VERSION ""

NS_ :

BS_:

BU_: Datalogger dSPACE

BO_ 7 New_Message_114: 8 Vector__XXX
 SG_ New_Signal_405 : 55|8@1+ (1,0) [0|0] "" Vector__XXX

BO_ 6 New_Message_113: 8 Vector__XXX
 SG_ New_Signal_404 : 39|8@1+ (1,0) [0|0] "" Vector__XXX

BO_ 5 New_Message_112: 8 Vector__XXX
 SG_ New_Signal_403 : 23|8@1+ (1,0) [0|0] "" Vector__XXX

BO_ 4 New_Message_111: 8 Vector__XXX
 SG_ New_Signal_402 : 7|8@1+ (1,0) [0|0] "" Vector__XXX

BO_ 3 New_Message_110: 8 Vector__XXX
 SG_ New_Signal_401 : 55|8@1+ (1,0) [0|0] "" Vector__XXX

BO_ 2 New_Message_109: 8 Vector__XXX
 SG_ New_Signal_400 : 39|8@1+ (1,0) [0|0] "" Vector__XXX

BO_ 1 New_Message_108: 8 Vector__XXX
 SG_ New_Signal_399 : 23|8@1+ (1,0) [0|0] "" Vector__XXX

BO_ 0 New_Message_107: 8 Vector__XXX
 SG_ New_Signal_398 : 7|8@1+ (1,0) [0|0] "" Vector__XXX

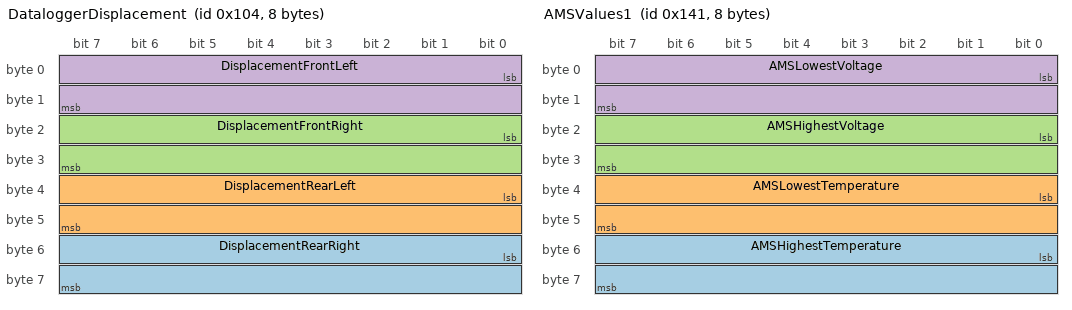
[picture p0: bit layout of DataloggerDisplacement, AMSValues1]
BO_ 260 DataloggerDisplacement: 8 Vector__XXX
 SG_ DisplacementRearRight : 48|16@1- (1,0) [0|0] "" Vector__XXX
 SG_ DisplacementRearLeft : 32|16@1- (1,0) [0|0] "" Vector__XXX
 SG_ DisplacementFrontRight : 16|16@1- (1,0) [0|0] "" Vector__XXX
 SG_ DisplacementFrontLeft : 0|16@1- (1,0) [0|0] "" Vector__XXX

BO_ 1319 EnergyMeterCurrentCounter: 6 Vector__XXX
 SG_ EMCurrentCounter : 23|32@0- (1,0) [0|0] "" Vector__XXX

BO_ 321 AMSValues1: 8 Vector__XXX
 SG_ AMSHighestTemperature : 48|16@1- (1,0) [0|0] "" Vector__XXX
 SG_ AMSLowestTemperature : 32|16@1- (1,0) [0|0] "" Vector__XXX
 SG_ AMSHighestVoltage : 16|16@1- (1,0) [0|0] "" Vector__XXX
 SG_ AMSLowestVoltage : 0|16@1- (1,0) [0|0] "" Vector__XXX

BO_ 1320 EnergyMeterEnergy: 6 Vector__XXX
 SG_ EMEnergy : 23|32@0- (1,0) [0|0] "" Vector__XXX

BO_ 1316 EnergyMeterVoltage3: 6 Vector__XXX
 SG_ EMVoltage3 : 23|32@0- (1,0) [0|0] "" Vector__XXX

BO_ 1315 EnergyMeterVoltageMC: 6 Vector__XXX
 SG_ EMVoltageMC : 7|32@0- (1,0) [0|0] "" Vector__XXX

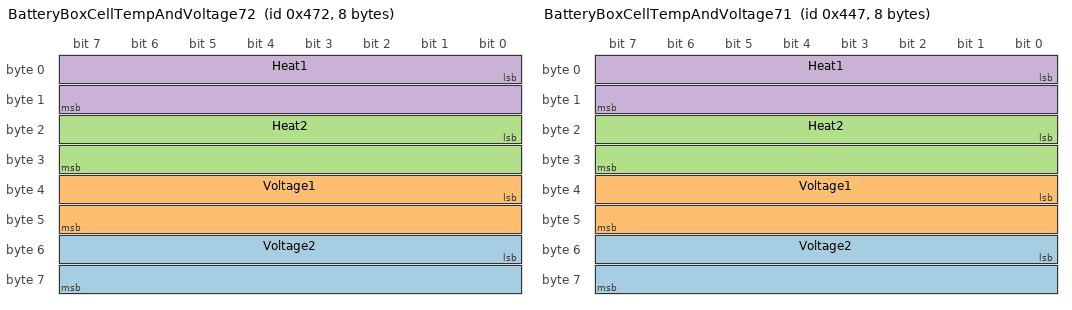
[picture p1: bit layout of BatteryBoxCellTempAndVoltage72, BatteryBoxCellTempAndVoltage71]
BO_ 1138 BatteryBoxCellTempAndVoltage72: 8 Vector__XXX
 SG_ Voltage2 : 48|16@1+ (0.001,0) [0|0] "" Vector__XXX
 SG_ Voltage1 : 32|16@1+ (0.001,0) [0|0] "" Vector__XXX
 SG_ Heat2 : 16|16@1+ (0.001,0) [0|0] "" Vector__XXX
 SG_ Heat1 : 0|16@1+ (0.001,0) [0|0] "" Vector__XXX

BO_ 1095 BatteryBoxCellTempAndVoltage71: 8 Vector__XXX
 SG_ Voltage2 : 48|16@1+ (0.001,0) [0|0] "" Vector__XXX
 SG_ Voltage1 : 32|16@1+ (0.001,0) [0|0] "" Vector__XXX
 SG_ Heat2 : 16|16@1+ (0.001,0) [0|0] "" Vector__XXX
 SG_ Heat1 : 0|16@1+ (0.001,0) [0|0] "" Vector__XXX

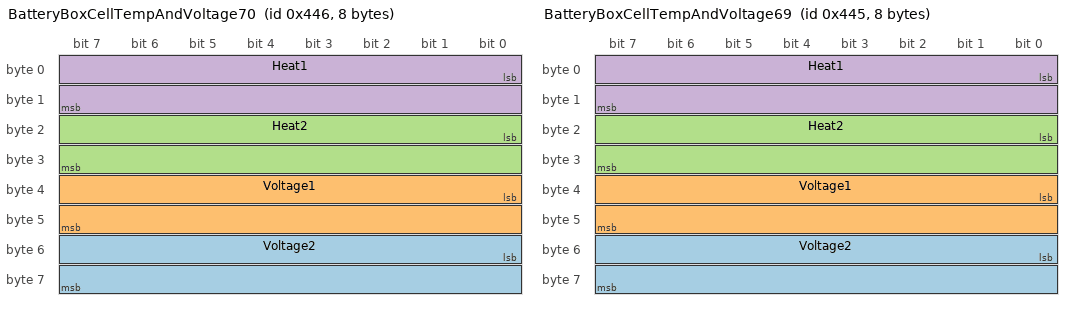
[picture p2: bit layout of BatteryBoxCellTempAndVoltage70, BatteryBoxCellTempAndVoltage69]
BO_ 1094 BatteryBoxCellTempAndVoltage70: 8 Vector__XXX
 SG_ Voltage2 : 48|16@1+ (0.001,0) [0|0] "" Vector__XXX
 SG_ Voltage1 : 32|16@1+ (0.001,0) [0|0] "" Vector__XXX
 SG_ Heat2 : 16|16@1+ (0.001,0) [0|0] "" Vector__XXX
 SG_ Heat1 : 0|16@1+ (0.001,0) [0|0] "" Vector__XXX

BO_ 1093 BatteryBoxCellTempAndVoltage69: 8 Vector__XXX
 SG_ Voltage2 : 48|16@1+ (0.001,0) [0|0] "" Vector__XXX
 SG_ Voltage1 : 32|16@1+ (0.001,0) [0|0] "" Vector__XXX
 SG_ Heat2 : 16|16@1+ (0.001,0) [0|0] "" Vector__XXX
 SG_ Heat1 : 0|16@1+ (0.001,0) [0|0] "" Vector__XXX

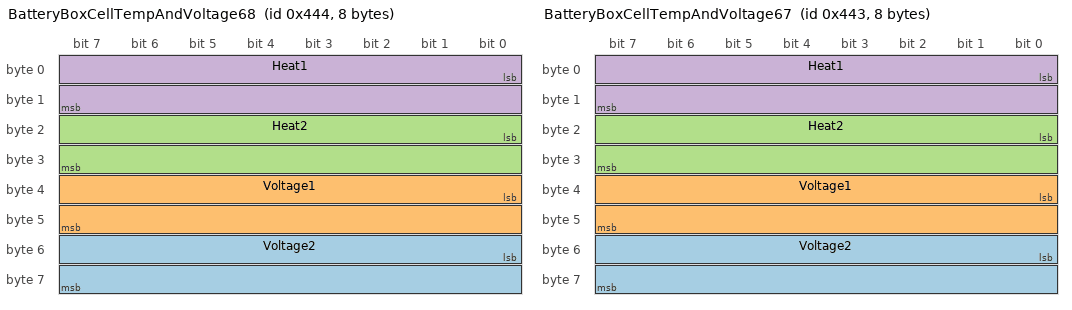
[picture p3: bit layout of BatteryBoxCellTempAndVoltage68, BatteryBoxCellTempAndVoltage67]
BO_ 1092 BatteryBoxCellTempAndVoltage68: 8 Vector__XXX
 SG_ Voltage2 : 48|16@1+ (0.001,0) [0|0] "" Vector__XXX
 SG_ Voltage1 : 32|16@1+ (0.001,0) [0|0] "" Vector__XXX
 SG_ Heat2 : 16|16@1+ (0.001,0) [0|0] "" Vector__XXX
 SG_ Heat1 : 0|16@1+ (0.001,0) [0|0] "" Vector__XXX

BO_ 1091 BatteryBoxCellTempAndVoltage67: 8 Vector__XXX
 SG_ Voltage2 : 48|16@1+ (0.001,0) [0|0] "" Vector__XXX
 SG_ Voltage1 : 32|16@1+ (0.001,0) [0|0] "" Vector__XXX
 SG_ Heat2 : 16|16@1+ (0.001,0) [0|0] "" Vector__XXX
 SG_ Heat1 : 0|16@1+ (0.001,0) [0|0] "" Vector__XXX

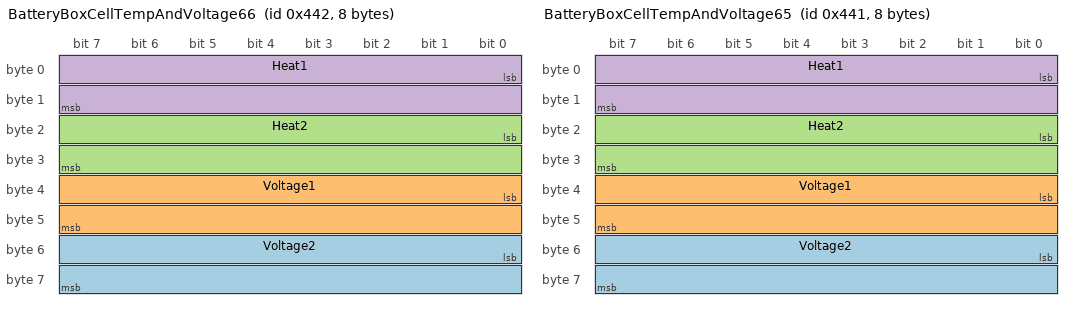
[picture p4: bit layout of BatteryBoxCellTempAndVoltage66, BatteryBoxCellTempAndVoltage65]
BO_ 1090 BatteryBoxCellTempAndVoltage66: 8 Vector__XXX
 SG_ Voltage2 : 48|16@1+ (0.001,0) [0|0] "" Vector__XXX
 SG_ Voltage1 : 32|16@1+ (0.001,0) [0|0] "" Vector__XXX
 SG_ Heat2 : 16|16@1+ (0.001,0) [0|0] "" Vector__XXX
 SG_ Heat1 : 0|16@1+ (0.001,0) [0|0] "" Vector__XXX

BO_ 1089 BatteryBoxCellTempAndVoltage65: 8 Vector__XXX
 SG_ Voltage2 : 48|16@1+ (0.001,0) [0|0] "" Vector__XXX
 SG_ Voltage1 : 32|16@1+ (0.001,0) [0|0] "" Vector__XXX
 SG_ Heat2 : 16|16@1+ (0.001,0) [0|0] "" Vector__XXX
 SG_ Heat1 : 0|16@1+ (0.001,0) [0|0] "" Vector__XXX

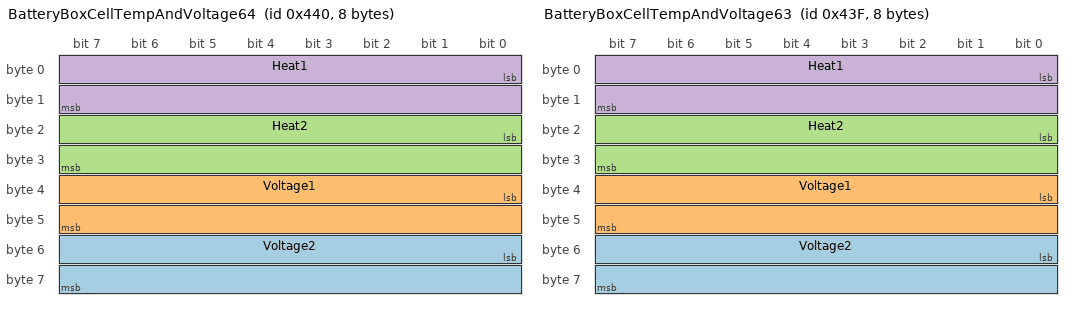
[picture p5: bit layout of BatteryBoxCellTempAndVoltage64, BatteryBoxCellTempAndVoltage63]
BO_ 1088 BatteryBoxCellTempAndVoltage64: 8 Vector__XXX
 SG_ Voltage2 : 48|16@1+ (0.001,0) [0|0] "" Vector__XXX
 SG_ Voltage1 : 32|16@1+ (0.001,0) [0|0] "" Vector__XXX
 SG_ Heat2 : 16|16@1+ (0.001,0) [0|0] "" Vector__XXX
 SG_ Heat1 : 0|16@1+ (0.001,0) [0|0] "" Vector__XXX

BO_ 1087 BatteryBoxCellTempAndVoltage63: 8 Vector__XXX
 SG_ Voltage2 : 48|16@1+ (0.001,0) [0|0] "" Vector__XXX
 SG_ Voltage1 : 32|16@1+ (0.001,0) [0|0] "" Vector__XXX
 SG_ Heat2 : 16|16@1+ (0.001,0) [0|0] "" Vector__XXX
 SG_ Heat1 : 0|16@1+ (0.001,0) [0|0] "" Vector__XXX

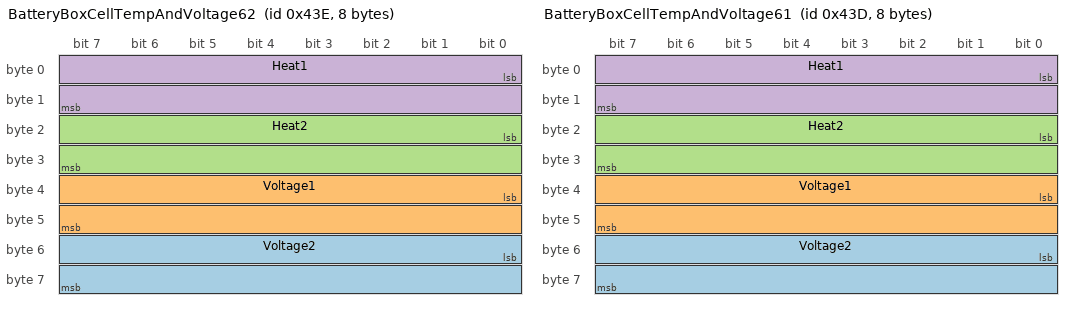
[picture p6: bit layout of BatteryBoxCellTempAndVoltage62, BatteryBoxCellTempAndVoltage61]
BO_ 1086 BatteryBoxCellTempAndVoltage62: 8 Vector__XXX
 SG_ Voltage2 : 48|16@1+ (0.001,0) [0|0] "" Vector__XXX
 SG_ Voltage1 : 32|16@1+ (0.001,0) [0|0] "" Vector__XXX
 SG_ Heat2 : 16|16@1+ (0.001,0) [0|0] "" Vector__XXX
 SG_ Heat1 : 0|16@1+ (0.001,0) [0|0] "" Vector__XXX

BO_ 1085 BatteryBoxCellTempAndVoltage61: 8 Vector__XXX
 SG_ Voltage2 : 48|16@1+ (0.001,0) [0|0] "" Vector__XXX
 SG_ Voltage1 : 32|16@1+ (0.001,0) [0|0] "" Vector__XXX
 SG_ Heat2 : 16|16@1+ (0.001,0) [0|0] "" Vector__XXX
 SG_ Heat1 : 0|16@1+ (0.001,0) [0|0] "" Vector__XXX

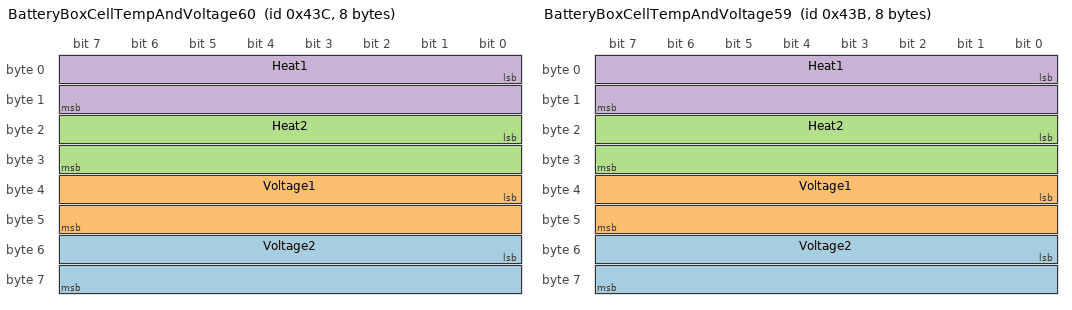
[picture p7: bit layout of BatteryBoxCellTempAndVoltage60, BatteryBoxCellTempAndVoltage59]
BO_ 1084 BatteryBoxCellTempAndVoltage60: 8 Vector__XXX
 SG_ Voltage2 : 48|16@1+ (0.001,0) [0|0] "" Vector__XXX
 SG_ Voltage1 : 32|16@1+ (0.001,0) [0|0] "" Vector__XXX
 SG_ Heat2 : 16|16@1+ (0.001,0) [0|0] "" Vector__XXX
 SG_ Heat1 : 0|16@1+ (0.001,0) [0|0] "" Vector__XXX

BO_ 1083 BatteryBoxCellTempAndVoltage59: 8 Vector__XXX
 SG_ Voltage2 : 48|16@1+ (0.001,0) [0|0] "" Vector__XXX
 SG_ Voltage1 : 32|16@1+ (0.001,0) [0|0] "" Vector__XXX
 SG_ Heat2 : 16|16@1+ (0.001,0) [0|0] "" Vector__XXX
 SG_ Heat1 : 0|16@1+ (0.001,0) [0|0] "" Vector__XXX

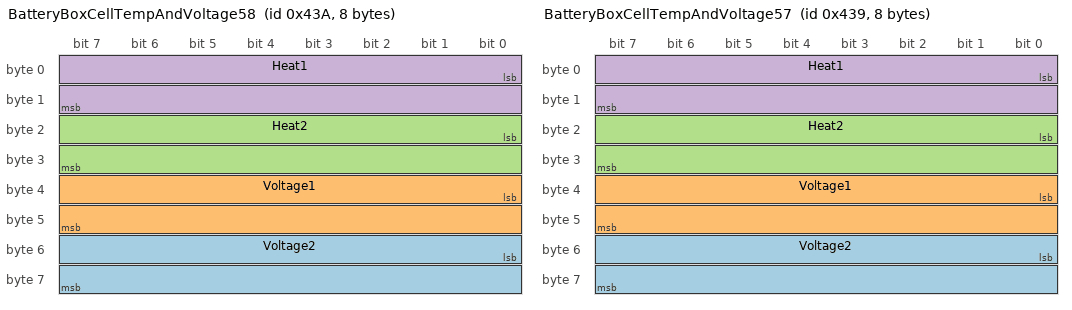
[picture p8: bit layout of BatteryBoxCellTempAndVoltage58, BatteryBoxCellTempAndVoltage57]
BO_ 1082 BatteryBoxCellTempAndVoltage58: 8 Vector__XXX
 SG_ Voltage2 : 48|16@1+ (0.001,0) [0|0] "" Vector__XXX
 SG_ Voltage1 : 32|16@1+ (0.001,0) [0|0] "" Vector__XXX
 SG_ Heat2 : 16|16@1+ (0.001,0) [0|0] "" Vector__XXX
 SG_ Heat1 : 0|16@1+ (0.001,0) [0|0] "" Vector__XXX

BO_ 1081 BatteryBoxCellTempAndVoltage57: 8 Vector__XXX
 SG_ Voltage2 : 48|16@1+ (0.001,0) [0|0] "" Vector__XXX
 SG_ Voltage1 : 32|16@1+ (0.001,0) [0|0] "" Vector__XXX
 SG_ Heat2 : 16|16@1+ (0.001,0) [0|0] "" Vector__XXX
 SG_ Heat1 : 0|16@1+ (0.001,0) [0|0] "" Vector__XXX

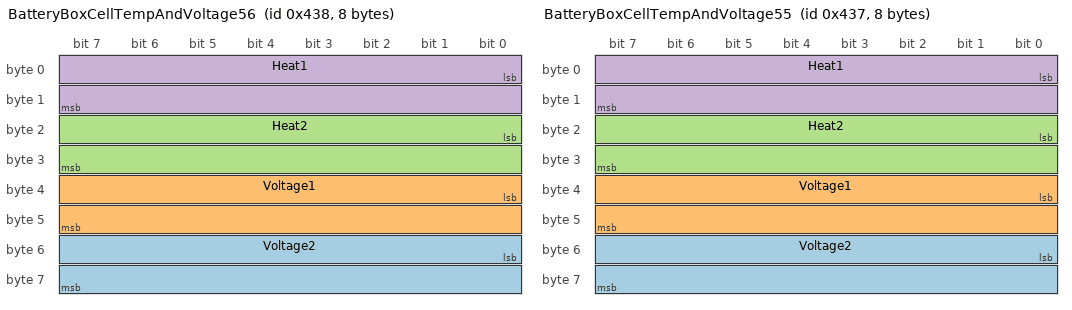
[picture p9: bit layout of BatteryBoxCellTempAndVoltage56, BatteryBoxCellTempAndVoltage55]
BO_ 1080 BatteryBoxCellTempAndVoltage56: 8 Vector__XXX
 SG_ Voltage2 : 48|16@1+ (0.001,0) [0|0] "" Vector__XXX
 SG_ Voltage1 : 32|16@1+ (0.001,0) [0|0] "" Vector__XXX
 SG_ Heat2 : 16|16@1+ (0.001,0) [0|0] "" Vector__XXX
 SG_ Heat1 : 0|16@1+ (0.001,0) [0|0] "" Vector__XXX

BO_ 1079 BatteryBoxCellTempAndVoltage55: 8 Vector__XXX
 SG_ Voltage2 : 48|16@1+ (0.001,0) [0|0] "" Vector__XXX
 SG_ Voltage1 : 32|16@1+ (0.001,0) [0|0] "" Vector__XXX
 SG_ Heat2 : 16|16@1+ (0.001,0) [0|0] "" Vector__XXX
 SG_ Heat1 : 0|16@1+ (0.001,0) [0|0] "" Vector__XXX

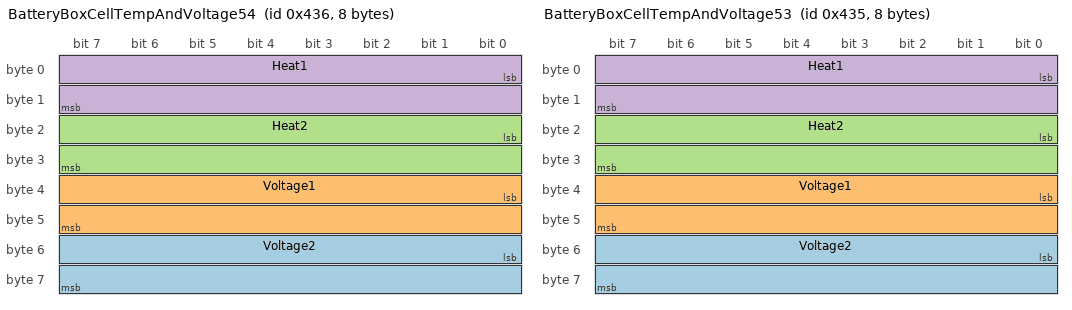
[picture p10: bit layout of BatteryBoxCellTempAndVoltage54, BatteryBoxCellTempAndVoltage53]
BO_ 1078 BatteryBoxCellTempAndVoltage54: 8 Vector__XXX
 SG_ Voltage2 : 48|16@1+ (0.001,0) [0|0] "" Vector__XXX
 SG_ Voltage1 : 32|16@1+ (0.001,0) [0|0] "" Vector__XXX
 SG_ Heat2 : 16|16@1+ (0.001,0) [0|0] "" Vector__XXX
 SG_ Heat1 : 0|16@1+ (0.001,0) [0|0] "" Vector__XXX

BO_ 1077 BatteryBoxCellTempAndVoltage53: 8 Vector__XXX
 SG_ Voltage2 : 48|16@1+ (0.001,0) [0|0] "" Vector__XXX
 SG_ Voltage1 : 32|16@1+ (0.001,0) [0|0] "" Vector__XXX
 SG_ Heat2 : 16|16@1+ (0.001,0) [0|0] "" Vector__XXX
 SG_ Heat1 : 0|16@1+ (0.001,0) [0|0] "" Vector__XXX

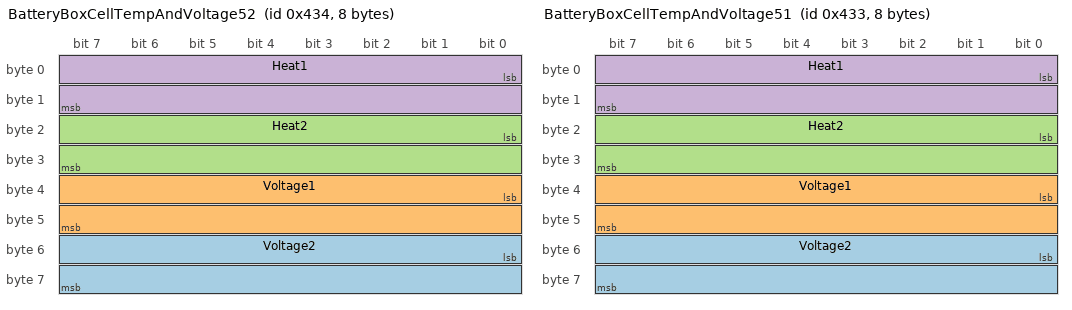
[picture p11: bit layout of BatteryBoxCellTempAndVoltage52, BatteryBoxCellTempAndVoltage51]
BO_ 1076 BatteryBoxCellTempAndVoltage52: 8 Vector__XXX
 SG_ Voltage2 : 48|16@1+ (0.001,0) [0|0] "" Vector__XXX
 SG_ Voltage1 : 32|16@1+ (0.001,0) [0|0] "" Vector__XXX
 SG_ Heat2 : 16|16@1+ (0.001,0) [0|0] "" Vector__XXX
 SG_ Heat1 : 0|16@1+ (0.001,0) [0|0] "" Vector__XXX

BO_ 1075 BatteryBoxCellTempAndVoltage51: 8 Vector__XXX
 SG_ Voltage2 : 48|16@1+ (0.001,0) [0|0] "" Vector__XXX
 SG_ Voltage1 : 32|16@1+ (0.001,0) [0|0] "" Vector__XXX
 SG_ Heat2 : 16|16@1+ (0.001,0) [0|0] "" Vector__XXX
 SG_ Heat1 : 0|16@1+ (0.001,0) [0|0] "" Vector__XXX

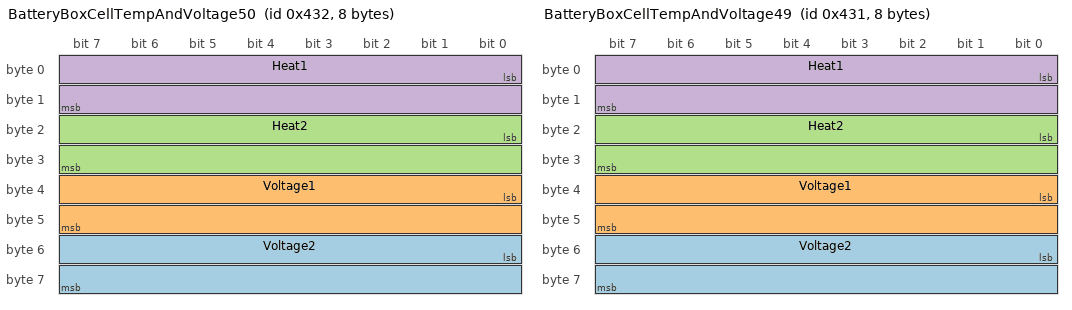
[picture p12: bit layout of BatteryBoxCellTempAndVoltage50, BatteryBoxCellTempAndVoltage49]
BO_ 1074 BatteryBoxCellTempAndVoltage50: 8 Vector__XXX
 SG_ Voltage2 : 48|16@1+ (0.001,0) [0|0] "" Vector__XXX
 SG_ Voltage1 : 32|16@1+ (0.001,0) [0|0] "" Vector__XXX
 SG_ Heat2 : 16|16@1+ (0.001,0) [0|0] "" Vector__XXX
 SG_ Heat1 : 0|16@1+ (0.001,0) [0|0] "" Vector__XXX

BO_ 1073 BatteryBoxCellTempAndVoltage49: 8 Vector__XXX
 SG_ Voltage2 : 48|16@1+ (0.001,0) [0|0] "" Vector__XXX
 SG_ Voltage1 : 32|16@1+ (0.001,0) [0|0] "" Vector__XXX
 SG_ Heat2 : 16|16@1+ (0.001,0) [0|0] "" Vector__XXX
 SG_ Heat1 : 0|16@1+ (0.001,0) [0|0] "" Vector__XXX

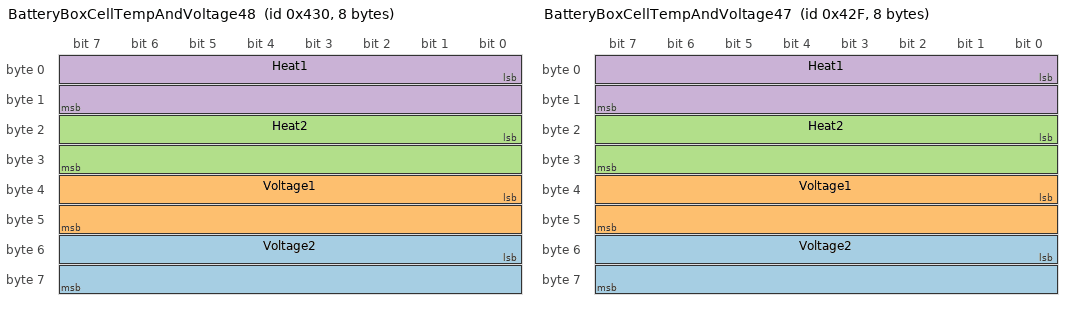
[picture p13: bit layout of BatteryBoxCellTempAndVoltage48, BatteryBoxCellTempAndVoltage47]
BO_ 1072 BatteryBoxCellTempAndVoltage48: 8 Vector__XXX
 SG_ Voltage2 : 48|16@1+ (0.001,0) [0|0] "" Vector__XXX
 SG_ Voltage1 : 32|16@1+ (0.001,0) [0|0] "" Vector__XXX
 SG_ Heat2 : 16|16@1+ (0.001,0) [0|0] "" Vector__XXX
 SG_ Heat1 : 0|16@1+ (0.001,0) [0|0] "" Vector__XXX

BO_ 1071 BatteryBoxCellTempAndVoltage47: 8 Vector__XXX
 SG_ Voltage2 : 48|16@1+ (0.001,0) [0|0] "" Vector__XXX
 SG_ Voltage1 : 32|16@1+ (0.001,0) [0|0] "" Vector__XXX
 SG_ Heat2 : 16|16@1+ (0.001,0) [0|0] "" Vector__XXX
 SG_ Heat1 : 0|16@1+ (0.001,0) [0|0] "" Vector__XXX

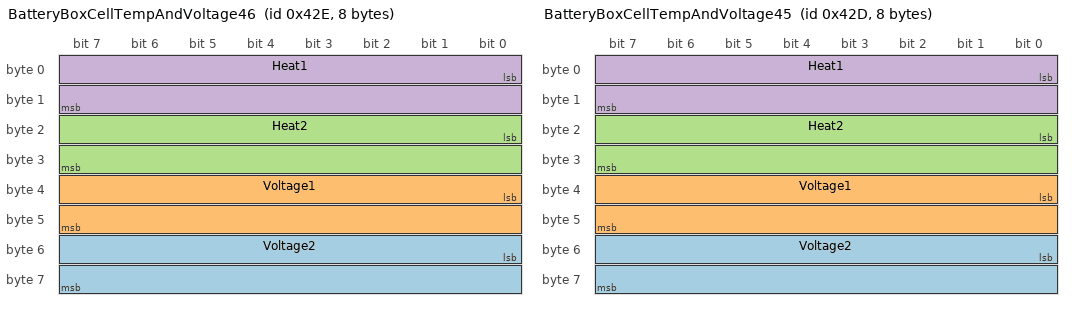
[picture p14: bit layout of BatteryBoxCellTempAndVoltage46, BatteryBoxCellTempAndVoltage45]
BO_ 1070 BatteryBoxCellTempAndVoltage46: 8 Vector__XXX
 SG_ Voltage2 : 48|16@1+ (0.001,0) [0|0] "" Vector__XXX
 SG_ Voltage1 : 32|16@1+ (0.001,0) [0|0] "" Vector__XXX
 SG_ Heat2 : 16|16@1+ (0.001,0) [0|0] "" Vector__XXX
 SG_ Heat1 : 0|16@1+ (0.001,0) [0|0] "" Vector__XXX

BO_ 1069 BatteryBoxCellTempAndVoltage45: 8 Vector__XXX
 SG_ Voltage2 : 48|16@1+ (0.001,0) [0|0] "" Vector__XXX
 SG_ Voltage1 : 32|16@1+ (0.001,0) [0|0] "" Vector__XXX
 SG_ Heat2 : 16|16@1+ (0.001,0) [0|0] "" Vector__XXX
 SG_ Heat1 : 0|16@1+ (0.001,0) [0|0] "" Vector__XXX

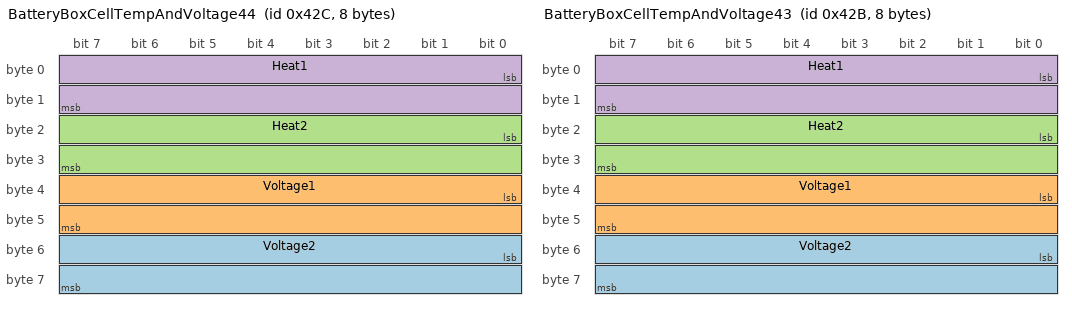
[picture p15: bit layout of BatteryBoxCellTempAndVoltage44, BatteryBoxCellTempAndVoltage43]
BO_ 1068 BatteryBoxCellTempAndVoltage44: 8 Vector__XXX
 SG_ Voltage2 : 48|16@1+ (0.001,0) [0|0] "" Vector__XXX
 SG_ Voltage1 : 32|16@1+ (0.001,0) [0|0] "" Vector__XXX
 SG_ Heat2 : 16|16@1+ (0.001,0) [0|0] "" Vector__XXX
 SG_ Heat1 : 0|16@1+ (0.001,0) [0|0] "" Vector__XXX

BO_ 1067 BatteryBoxCellTempAndVoltage43: 8 Vector__XXX
 SG_ Voltage2 : 48|16@1+ (0.001,0) [0|0] "" Vector__XXX
 SG_ Voltage1 : 32|16@1+ (0.001,0) [0|0] "" Vector__XXX
 SG_ Heat2 : 16|16@1+ (0.001,0) [0|0] "" Vector__XXX
 SG_ Heat1 : 0|16@1+ (0.001,0) [0|0] "" Vector__XXX

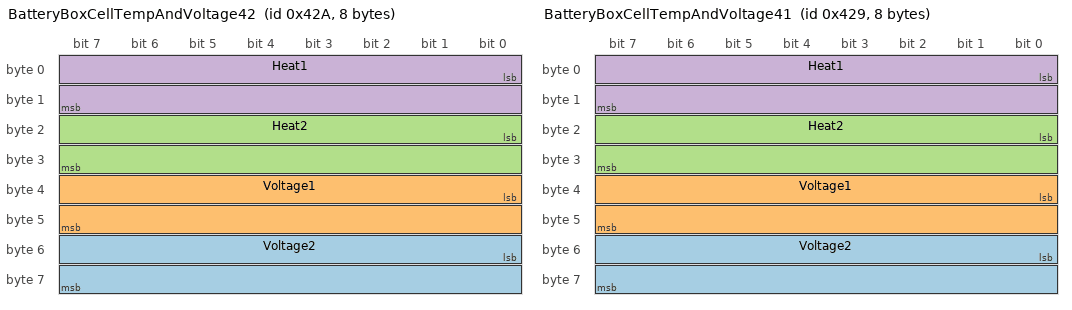
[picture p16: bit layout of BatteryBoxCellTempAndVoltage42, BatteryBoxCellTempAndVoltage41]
BO_ 1066 BatteryBoxCellTempAndVoltage42: 8 Vector__XXX
 SG_ Voltage2 : 48|16@1+ (0.001,0) [0|0] "" Vector__XXX
 SG_ Voltage1 : 32|16@1+ (0.001,0) [0|0] "" Vector__XXX
 SG_ Heat2 : 16|16@1+ (0.001,0) [0|0] "" Vector__XXX
 SG_ Heat1 : 0|16@1+ (0.001,0) [0|0] "" Vector__XXX

BO_ 1065 BatteryBoxCellTempAndVoltage41: 8 Vector__XXX
 SG_ Voltage2 : 48|16@1+ (0.001,0) [0|0] "" Vector__XXX
 SG_ Voltage1 : 32|16@1+ (0.001,0) [0|0] "" Vector__XXX
 SG_ Heat2 : 16|16@1+ (0.001,0) [0|0] "" Vector__XXX
 SG_ Heat1 : 0|16@1+ (0.001,0) [0|0] "" Vector__XXX

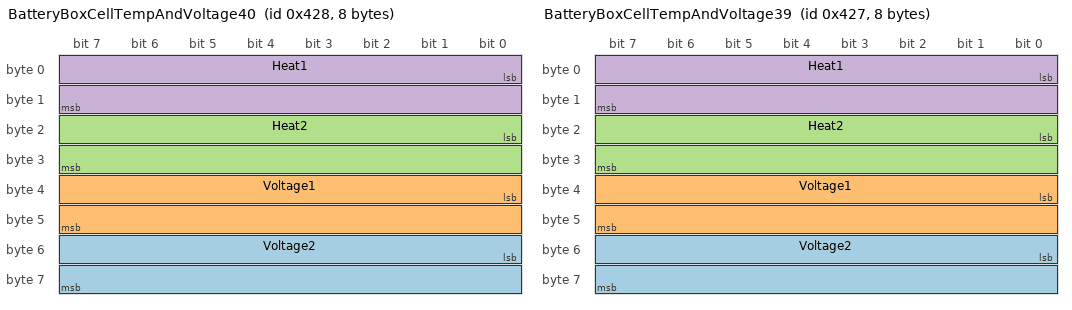
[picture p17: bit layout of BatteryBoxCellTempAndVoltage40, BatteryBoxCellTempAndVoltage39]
BO_ 1064 BatteryBoxCellTempAndVoltage40: 8 Vector__XXX
 SG_ Voltage2 : 48|16@1+ (0.001,0) [0|0] "" Vector__XXX
 SG_ Voltage1 : 32|16@1+ (0.001,0) [0|0] "" Vector__XXX
 SG_ Heat2 : 16|16@1+ (0.001,0) [0|0] "" Vector__XXX
 SG_ Heat1 : 0|16@1+ (0.001,0) [0|0] "" Vector__XXX

BO_ 1063 BatteryBoxCellTempAndVoltage39: 8 Vector__XXX
 SG_ Voltage2 : 48|16@1+ (0.001,0) [0|0] "" Vector__XXX
 SG_ Voltage1 : 32|16@1+ (0.001,0) [0|0] "" Vector__XXX
 SG_ Heat2 : 16|16@1+ (0.001,0) [0|0] "" Vector__XXX
 SG_ Heat1 : 0|16@1+ (0.001,0) [0|0] "" Vector__XXX

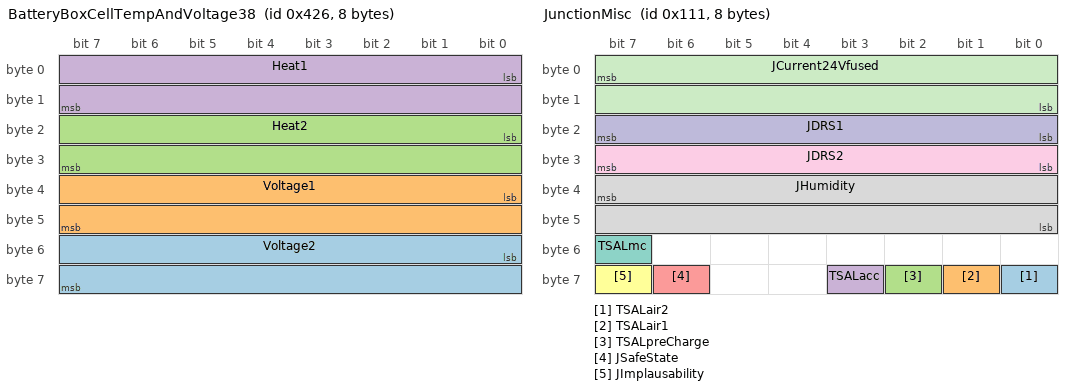
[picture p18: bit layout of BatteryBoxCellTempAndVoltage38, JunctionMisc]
BO_ 1062 BatteryBoxCellTempAndVoltage38: 8 Vector__XXX
 SG_ Voltage2 : 48|16@1+ (0.001,0) [0|0] "" Vector__XXX
 SG_ Voltage1 : 32|16@1+ (0.001,0) [0|0] "" Vector__XXX
 SG_ Heat2 : 16|16@1+ (0.001,0) [0|0] "" Vector__XXX
 SG_ Heat1 : 0|16@1+ (0.001,0) [0|0] "" Vector__XXX

BO_ 1061 BatteryBoxCellTempAndVoltage37: 8 Vector__XXX
 SG_ Voltage2 : 48|16@1+ (0.001,0) [0|0] "" Vector__XXX
 SG_ Voltage1 : 32|16@1+ (0.001,0) [0|0] "" Vector__XXX
 SG_ Heat2 : 16|16@1+ (0.001,0) [0|0] "" Vector__XXX
 SG_ Heat1 : 0|16@1+ (0.001,0) [0|0] "" Vector__XXX

BO_ 1060 BatteryBoxCellTempAndVoltage36: 8 Vector__XXX
 SG_ Voltage2 : 48|16@1+ (0.001,0) [0|0] "" Vector__XXX
 SG_ Voltage1 : 32|16@1+ (0.001,0) [0|0] "" Vector__XXX
 SG_ Heat2 : 16|16@1+ (0.001,0) [0|0] "" Vector__XXX
 SG_ Heat1 : 0|16@1+ (0.001,0) [0|0] "" Vector__XXX

BO_ 1059 BatteryBoxCellTempAndVoltage35: 8 Vector__XXX
 SG_ Voltage2 : 48|16@1+ (0.001,0) [0|0] "" Vector__XXX
 SG_ Voltage1 : 32|16@1+ (0.001,0) [0|0] "" Vector__XXX
 SG_ Heat2 : 16|16@1+ (0.001,0) [0|0] "" Vector__XXX
 SG_ Heat1 : 0|16@1+ (0.001,0) [0|0] "" Vector__XXX

BO_ 1058 BatteryBoxCellTempAndVoltage34: 8 Vector__XXX
 SG_ Voltage2 : 48|16@1+ (0.001,0) [0|0] "" Vector__XXX
 SG_ Voltage1 : 32|16@1+ (0.001,0) [0|0] "" Vector__XXX
 SG_ Heat2 : 16|16@1+ (0.001,0) [0|0] "" Vector__XXX
 SG_ Heat1 : 0|16@1+ (0.001,0) [0|0] "" Vector__XXX

BO_ 1057 BatteryBoxCellTempAndVoltage33: 8 Vector__XXX
 SG_ Voltage2 : 48|16@1+ (0.001,0) [0|0] "" Vector__XXX
 SG_ Voltage1 : 32|16@1+ (0.001,0) [0|0] "" Vector__XXX
 SG_ Heat2 : 16|16@1+ (0.001,0) [0|0] "" Vector__XXX
 SG_ Heat1 : 0|16@1+ (0.001,0) [0|0] "" Vector__XXX

BO_ 1056 BatteryBoxCellTempAndVoltage32: 8 Vector__XXX
 SG_ Voltage2 : 48|16@1+ (0.001,0) [0|0] "" Vector__XXX
 SG_ Voltage1 : 32|16@1+ (0.001,0) [0|0] "" Vector__XXX
 SG_ Heat2 : 16|16@1+ (0.001,0) [0|0] "" Vector__XXX
 SG_ Heat1 : 0|16@1+ (0.001,0) [0|0] "" Vector__XXX

BO_ 1055 BatteryBoxCellTempAndVoltage31: 8 Vector__XXX
 SG_ Voltage2 : 48|16@1+ (0.001,0) [0|0] "" Vector__XXX
 SG_ Voltage1 : 32|16@1+ (0.001,0) [0|0] "" Vector__XXX
 SG_ Heat2 : 16|16@1+ (0.001,0) [0|0] "" Vector__XXX
 SG_ Heat1 : 0|16@1+ (0.001,0) [0|0] "" Vector__XXX

BO_ 1054 BatteryBoxCellTempAndVoltage30: 8 Vector__XXX
 SG_ Voltage2 : 48|16@1+ (0.001,0) [0|0] "" Vector__XXX
 SG_ Voltage1 : 32|16@1+ (0.001,0) [0|0] "" Vector__XXX
 SG_ Heat2 : 16|16@1+ (0.001,0) [0|0] "" Vector__XXX
 SG_ Heat1 : 0|16@1+ (0.001,0) [0|0] "" Vector__XXX

BO_ 1053 BatteryBoxCellTempAndVoltage29: 8 Vector__XXX
 SG_ Voltage2 : 48|16@1+ (0.001,0) [0|0] "" Vector__XXX
 SG_ Voltage1 : 32|16@1+ (0.001,0) [0|0] "" Vector__XXX
 SG_ Heat2 : 16|16@1+ (0.001,0) [0|0] "" Vector__XXX
 SG_ Heat1 : 0|16@1+ (0.001,0) [0|0] "" Vector__XXX

BO_ 1052 BatteryBoxCellTempAndVoltage28: 8 Vector__XXX
 SG_ Voltage2 : 48|16@1+ (0.001,0) [0|0] "" Vector__XXX
 SG_ Voltage1 : 32|16@1+ (0.001,0) [0|0] "" Vector__XXX
 SG_ Heat2 : 16|16@1+ (0.001,0) [0|0] "" Vector__XXX
 SG_ Heat1 : 0|16@1+ (0.001,0) [0|0] "" Vector__XXX

BO_ 1051 BatteryBoxCellTempAndVoltage27: 8 Vector__XXX
 SG_ Voltage2 : 48|16@1+ (0.001,0) [0|0] "" Vector__XXX
 SG_ Voltage1 : 32|16@1+ (0.001,0) [0|0] "" Vector__XXX
 SG_ Heat2 : 16|16@1+ (0.001,0) [0|0] "" Vector__XXX
 SG_ Heat1 : 0|16@1+ (0.001,0) [0|0] "" Vector__XXX

BO_ 1050 BatteryBoxCellTempAndVoltage26: 8 Vector__XXX
 SG_ Voltage2 : 48|16@1+ (0.001,0) [0|0] "" Vector__XXX
 SG_ Voltage1 : 32|16@1+ (0.001,0) [0|0] "" Vector__XXX
 SG_ Heat2 : 16|16@1+ (0.001,0) [0|0] "" Vector__XXX
 SG_ Heat1 : 0|16@1+ (0.001,0) [0|0] "" Vector__XXX

BO_ 1049 BatteryBoxCellTempAndVoltage25: 8 Vector__XXX
 SG_ Voltage2 : 48|16@1+ (0.001,0) [0|0] "" Vector__XXX
 SG_ Voltage1 : 32|16@1+ (0.001,0) [0|0] "" Vector__XXX
 SG_ Heat2 : 16|16@1+ (0.001,0) [0|0] "" Vector__XXX
 SG_ Heat1 : 0|16@1+ (0.001,0) [0|0] "" Vector__XXX

BO_ 1048 BatteryBoxCellTempAndVoltage24: 8 Vector__XXX
 SG_ Voltage2 : 48|16@1+ (0.001,0) [0|0] "" Vector__XXX
 SG_ Voltage1 : 32|16@1+ (0.001,0) [0|0] "" Vector__XXX
 SG_ Heat2 : 16|16@1+ (0.001,0) [0|0] "" Vector__XXX
 SG_ Heat1 : 0|16@1+ (0.001,0) [0|0] "" Vector__XXX

BO_ 1047 BatteryBoxCellTempAndVoltage23: 8 Vector__XXX
 SG_ Voltage2 : 48|16@1+ (0.001,0) [0|0] "" Vector__XXX
 SG_ Voltage1 : 32|16@1+ (0.001,0) [0|0] "" Vector__XXX
 SG_ Heat2 : 16|16@1+ (0.001,0) [0|0] "" Vector__XXX
 SG_ Heat1 : 0|16@1+ (0.001,0) [0|0] "" Vector__XXX

BO_ 1046 BatteryBoxCellTempAndVoltage22: 8 Vector__XXX
 SG_ Voltage2 : 48|16@1+ (0.001,0) [0|0] "" Vector__XXX
 SG_ Voltage1 : 32|16@1+ (0.001,0) [0|0] "" Vector__XXX
 SG_ Heat2 : 16|16@1+ (0.001,0) [0|0] "" Vector__XXX
 SG_ Heat1 : 0|16@1+ (0.001,0) [0|0] "" Vector__XXX

BO_ 1045 BatteryBoxCellTempAndVoltage21: 8 Vector__XXX
 SG_ Voltage2 : 48|16@1+ (0.001,0) [0|0] "" Vector__XXX
 SG_ Voltage1 : 32|16@1+ (0.001,0) [0|0] "" Vector__XXX
 SG_ Heat2 : 16|16@1+ (0.001,0) [0|0] "" Vector__XXX
 SG_ Heat1 : 0|16@1+ (0.001,0) [0|0] "" Vector__XXX

BO_ 1044 BatteryBoxCellTempAndVoltage20: 8 Vector__XXX
 SG_ Voltage2 : 48|16@1+ (0.001,0) [0|0] "" Vector__XXX
 SG_ Voltage1 : 32|16@1+ (0.001,0) [0|0] "" Vector__XXX
 SG_ Heat2 : 16|16@1+ (0.001,0) [0|0] "" Vector__XXX
 SG_ Heat1 : 0|16@1+ (0.001,0) [0|0] "" Vector__XXX

BO_ 1043 BatteryBoxCellTempAndVoltage19: 8 Vector__XXX
 SG_ Voltage2 : 48|16@1+ (0.001,0) [0|0] "" Vector__XXX
 SG_ Voltage1 : 32|16@1+ (0.001,0) [0|0] "" Vector__XXX
 SG_ Heat2 : 16|16@1+ (0.001,0) [0|0] "" Vector__XXX
 SG_ Heat1 : 0|16@1+ (0.001,0) [0|0] "" Vector__XXX

BO_ 1042 BatteryBoxCellTempAndVoltage18: 8 Vector__XXX
 SG_ Voltage2 : 48|16@1+ (0.001,0) [0|0] "" Vector__XXX
 SG_ Voltage1 : 32|16@1+ (0.001,0) [0|0] "" Vector__XXX
 SG_ Heat2 : 16|16@1+ (0.001,0) [0|0] "" Vector__XXX
 SG_ Heat1 : 0|16@1+ (0.001,0) [0|0] "" Vector__XXX

BO_ 1024 BatteryBoxCellTempAndVoltage17: 8 Vector__XXX
 SG_ Voltage2 : 48|16@1+ (0.001,0) [0|0] "" Vector__XXX
 SG_ Voltage1 : 32|16@1+ (0.001,0) [0|0] "" Vector__XXX
 SG_ Heat2 : 16|16@1+ (0.001,0) [0|0] "" Vector__XXX
 SG_ Heat1 : 0|16@1+ (0.001,0) [0|0] "" Vector__XXX

BO_ 1040 BatteryBoxCellTempAndVoltage16: 8 Vector__XXX
 SG_ Voltage2 : 48|16@1+ (0.001,0) [0|0] "" Vector__XXX
 SG_ Voltage1 : 32|16@1+ (0.001,0) [0|0] "" Vector__XXX
 SG_ Heat2 : 16|16@1+ (0.001,0) [0|0] "" Vector__XXX
 SG_ Heat1 : 0|16@1+ (0.001,0) [0|0] "" Vector__XXX

BO_ 1039 BatteryBoxCellTempAndVoltage15: 8 Vector__XXX
 SG_ Voltage2 : 48|16@1+ (0.001,0) [0|0] "" Vector__XXX
 SG_ Voltage1 : 32|16@1+ (0.001,0) [0|0] "" Vector__XXX
 SG_ Heat2 : 16|16@1+ (0.001,0) [0|0] "" Vector__XXX
 SG_ Heat1 : 0|16@1+ (0.001,0) [0|0] "" Vector__XXX

BO_ 1038 BatteryBoxCellTempAndVoltage14: 8 Vector__XXX
 SG_ Voltage2 : 48|16@1+ (0.001,0) [0|0] "" Vector__XXX
 SG_ Voltage1 : 32|16@1+ (0.001,0) [0|0] "" Vector__XXX
 SG_ Heat2 : 16|16@1+ (0.001,0) [0|0] "" Vector__XXX
 SG_ Heat1 : 0|16@1+ (0.001,0) [0|0] "" Vector__XXX

BO_ 1037 BatteryBoxCellTempAndVoltage13: 8 Vector__XXX
 SG_ Voltage2 : 48|16@1+ (0.001,0) [0|0] "" Vector__XXX
 SG_ Voltage1 : 32|16@1+ (0.001,0) [0|0] "" Vector__XXX
 SG_ Heat2 : 16|16@1+ (0.001,0) [0|0] "" Vector__XXX
 SG_ Heat1 : 0|16@1+ (0.001,0) [0|0] "" Vector__XXX

BO_ 1036 BatteryBoxCellTempAndVoltage12: 8 Vector__XXX
 SG_ Voltage2 : 48|16@1+ (0.001,0) [0|0] "" Vector__XXX
 SG_ Voltage1 : 32|16@1+ (0.001,0) [0|0] "" Vector__XXX
 SG_ Heat2 : 16|16@1+ (0.001,0) [0|0] "" Vector__XXX
 SG_ Heat1 : 0|16@1+ (0.001,0) [0|0] "" Vector__XXX

BO_ 1035 BatteryBoxCellTempAndVoltage11: 8 Vector__XXX
 SG_ Voltage2 : 48|16@1+ (0.001,0) [0|0] "" Vector__XXX
 SG_ Voltage1 : 32|16@1+ (0.001,0) [0|0] "" Vector__XXX
 SG_ Heat2 : 16|16@1+ (0.001,0) [0|0] "" Vector__XXX
 SG_ Heat1 : 0|16@1+ (0.001,0) [0|0] "" Vector__XXX

BO_ 1034 BatteryBoxCellTempAndVoltage10: 8 Vector__XXX
 SG_ Voltage2 : 48|16@1+ (0.001,0) [0|0] "" Vector__XXX
 SG_ Voltage1 : 32|16@1+ (0.001,0) [0|0] "" Vector__XXX
 SG_ Heat2 : 16|16@1+ (0.001,0) [0|0] "" Vector__XXX
 SG_ Heat1 : 0|16@1+ (0.001,0) [0|0] "" Vector__XXX

BO_ 1033 BatteryBoxCellTempAndVoltage9: 8 Vector__XXX
 SG_ Voltage2 : 48|16@1+ (0.001,0) [0|0] "" Vector__XXX
 SG_ Voltage1 : 32|16@1+ (0.001,0) [0|0] "" Vector__XXX
 SG_ Heat2 : 16|16@1+ (0.001,0) [0|0] "" Vector__XXX
 SG_ Heat1 : 0|16@1+ (0.001,0) [0|0] "" Vector__XXX

BO_ 1032 BatteryBoxCellTempAndVoltage8: 8 Vector__XXX
 SG_ Voltage2 : 48|16@1+ (0.001,0) [0|0] "" Vector__XXX
 SG_ Voltage1 : 32|16@1+ (0.001,0) [0|0] "" Vector__XXX
 SG_ Heat2 : 16|16@1+ (0.001,0) [0|0] "" Vector__XXX
 SG_ Heat1 : 0|16@1+ (0.001,0) [0|0] "" Vector__XXX

BO_ 1031 BatteryBoxCellTempAndVoltage7: 8 Vector__XXX
 SG_ Voltage2 : 48|16@1+ (0.001,0) [0|0] "" Vector__XXX
 SG_ Voltage1 : 32|16@1+ (0.001,0) [0|0] "" Vector__XXX
 SG_ Heat2 : 16|16@1+ (0.001,0) [0|0] "" Vector__XXX
 SG_ Heat1 : 0|16@1+ (0.001,0) [0|0] "" Vector__XXX

BO_ 1030 BatteryBoxCellTempAndVoltage6: 8 Vector__XXX
 SG_ Voltage2 : 48|16@1+ (0.001,0) [0|0] "" Vector__XXX
 SG_ Voltage1 : 32|16@1+ (0.001,0) [0|0] "" Vector__XXX
 SG_ Heat2 : 16|16@1+ (0.001,0) [0|0] "" Vector__XXX
 SG_ Heat1 : 0|16@1+ (0.001,0) [0|0] "" Vector__XXX

BO_ 1029 BatteryBoxCellTempAndVoltage5: 8 Vector__XXX
 SG_ Voltage2 : 48|16@1+ (0.001,0) [0|0] "" Vector__XXX
 SG_ Voltage1 : 32|16@1+ (0.001,0) [0|0] "" Vector__XXX
 SG_ Heat2 : 16|16@1+ (0.001,0) [0|0] "" Vector__XXX
 SG_ Heat1 : 0|16@1+ (0.001,0) [0|0] "" Vector__XXX

BO_ 1028 BatteryBoxCellTempAndVoltage4: 8 Vector__XXX
 SG_ Voltage2 : 48|16@1+ (0.001,0) [0|0] "" Vector__XXX
 SG_ Voltage1 : 32|16@1+ (0.001,0) [0|0] "" Vector__XXX
 SG_ Heat2 : 16|16@1+ (0.001,0) [0|0] "" Vector__XXX
 SG_ Heat1 : 0|16@1+ (0.001,0) [0|0] "" Vector__XXX

BO_ 1027 BatteryBoxCellTempAndVoltage3: 8 Vector__XXX
 SG_ Voltage2 : 48|16@1+ (0.001,0) [0|0] "" Vector__XXX
 SG_ Voltage1 : 32|16@1+ (0.001,0) [0|0] "" Vector__XXX
 SG_ Heat2 : 16|16@1+ (0.001,0) [0|0] "" Vector__XXX
 SG_ Heat1 : 0|16@1+ (0.001,0) [0|0] "" Vector__XXX

BO_ 1026 BatteryBoxCellTempAndVoltage2: 8 Vector__XXX
 SG_ Voltage2 : 48|16@1+ (0.001,0) [0|0] "" Vector__XXX
 SG_ Voltage1 : 32|16@1+ (0.001,0) [0|0] "" Vector__XXX
 SG_ Heat2 : 16|16@1+ (0.001,0) [0|0] "" Vector__XXX
 SG_ Heat1 : 0|16@1+ (0.001,0) [0|0] "" Vector__XXX

BO_ 1025 BatteryBoxCellTempAndVoltage1: 8 Vector__XXX
 SG_ Voltage2 : 48|16@1+ (0.001,0) [0|0] "" Vector__XXX
 SG_ Voltage1 : 32|16@1+ (0.001,0) [0|0] "" Vector__XXX
 SG_ Heat2 : 16|16@1+ (0.001,0) [0|0] "" Vector__XXX
 SG_ Heat1 : 0|16@1+ (0.001,0) [0|0] "" Vector__XXX

BO_ 322 AMSValues2: 8 Vector__XXX
 SG_ BMSBadCellID : 56|8@1+ (1,0) [0|0] "" Vector__XXX
 SG_ BMSTempPECCount : 48|8@1+ (1,0) [0|0] "" Vector__XXX
 SG_ BMSVoltagePECCount : 40|8@1+ (1,0) [0|0] "" Vector__XXX
 SG_ BMSHighCurrentHerror : 39|1@1+ (1,0) [0|0] "" Vector__XXX
 SG_ BMSLowCurrentError : 38|1@1+ (1,0) [0|0] "" Vector__XXX
 SG_ BMSPECTempError : 37|1@1+ (1,0) [0|0] "" Vector__XXX
 SG_ BMSLowTempError : 36|1@1+ (1,0) [0|0] "" Vector__XXX
 SG_ BMSHighTempError : 35|1@1+ (1,0) [0|0] "" Vector__XXX
 SG_ BMSPECVoltageError : 34|1@1+ (1,0) [0|0] "" Vector__XXX
 SG_ BMSHighVoltageError : 33|1@1+ (1,0) [0|0] "" Vector__XXX
 SG_ BMSLowVoltageError : 32|1@1+ (1,0) [0|0] "" Vector__XXX
 SG_ AMSMeanVoltage : 16|16@1- (1,0) [0|0] "" Vector__XXX
 SG_ AMStsmsOut : 8|1@0- (1,0) [0|0] "" Vector__XXX
 SG_ AMSstatus4 : 9|1@0- (1,0) [0|0] "" Vector__XXX
 SG_ AMSstatus3 : 10|1@0- (1,0) [0|0] "" Vector__XXX
 SG_ AMSstatus2 : 11|1@0- (1,0) [0|0] "" Vector__XXX
 SG_ AMSstatus1 : 12|1@0- (1,0) [0|0] "" Vector__XXX
 SG_ AMSsdcTrigger : 13|1@0- (1,0) [0|0] "" Vector__XXX
 SG_ AMSsdcReset : 14|1@0- (1,0) [0|0] "" Vector__XXX
 SG_ AMSindicatorReset : 0|1@0- (1,0) [0|0] "" Vector__XXX
 SG_ AMSindicator : 1|1@0- (1,0) [0|0] "" Vector__XXX
 SG_ AMSimdIndicator : 2|1@0- (1,0) [0|0] "" Vector__XXX
 SG_ AMSimdError : 3|1@0- (1,0) [0|0] "" Vector__XXX
 SG_ AMSerror : 4|1@0- (1,0) [0|0] "" Vector__XXX
 SG_ AMSdriverReset : 5|1@0- (1,0) [0|0] "" Vector__XXX
 SG_ AMSairGround : 6|1@0- (1,0) [0|0] "" Vector__XXX
 SG_ AMSaccFanControl : 7|1@0- (1,0) [0|0] "" Vector__XXX

BO_ 320 AMSTempCurrent: 8 Vector__XXX
 SG_ AMSboardTemp : 55|16@0- (1,0) [0|0] "" Vector__XXX
 SG_ AMSCurrent : 39|16@0- (1,0) [0|0] "" Vector__XXX
 SG_ AMSDCDCtemp : 23|16@0- (1,0) [0|0] "" Vector__XXX
 SG_ AMSHumidity : 7|16@0- (1,0) [0|0] "" Vector__XXX

BO_ 273 JunctionMisc: 8 Vector__XXX
 SG_ TSALair2 : 56|1@0- (1,0) [0|0] "" Vector__XXX
 SG_ TSALair1 : 57|1@0- (1,0) [0|0] "" Vector__XXX
 SG_ TSALpreCharge : 58|1@0- (1,0) [0|0] "" Vector__XXX
 SG_ TSALacc : 59|1@0- (1,0) [0|0] "" Vector__XXX
 SG_ JSafeState : 62|1@0- (1,0) [0|0] "" Vector__XXX
 SG_ JImplausability : 63|1@0- (1,0) [0|0] "" Vector__XXX
 SG_ TSALmc : 55|1@0- (1,0) [0|0] "" Vector__XXX
 SG_ JHumidity : 39|16@0- (1,0) [0|0] "" Vector__XXX
 SG_ JDRS2 : 31|8@0- (1,0) [0|0] "" Vector__XXX
 SG_ JDRS1 : 23|8@0- (1,0) [0|0] "" Vector__XXX
 SG_ JCurrent24Vfused : 7|16@0- (1,0) [0|0] "" Vector__XXX

BO_ 272 JunctionCurrent: 8 Vector__XXX
 SG_ JCurrentMClv : 55|16@0- (1,0) [0|0] "" Vector__XXX
 SG_ JCurrentdSpace : 39|16@0- (1,0) [0|0] "" Vector__XXX
 SG_ JCurrent5V : 23|16@0- (1,0) [0|0] "" Vector__XXX
 SG_ JCurrent12V : 7|16@0- (1,0) [0|0] "" Vector__XXX

BO_ 336 DasboardButtons: 1 Vector__XXX
 SG_ DBButton2 : 6|1@0- (1,0) [0|0] "" Vector__XXX
 SG_ DBButton1 : 7|1@0- (1,0) [0|0] "" Vector__XXX

BO_ 258 DataloggerAcceleration: 8 Vector__XXX
 SG_ DLgpsSpeed : 55|16@0- (0.1,0) [0|0] "" Vector__XXX
 SG_ DLSteeringAngle : 39|16@0- (0.01,0) [0|0] "" Vector__XXX
 SG_ DLLinlineAcceleration : 23|16@0- (0.01,0) [0|0] "" Vector__XXX
 SG_ DLLateralAcceleration : 7|16@0- (0.01,0) [0|0] "" Vector__XXX

BO_ 259 DataloggerLaptime: 2 Vector__XXX
 SG_ DLLaptime : 7|16@0- (1,0) [0|0] "" Vector__XXX

BO_ 257 DataloggerRPM: 8 Vector__XXX
 SG_ DLrpmFrontLeft : 55|16@0- (1,0) [0|0] "" Vector__XXX
 SG_ DLrpmFrontRight : 39|16@0- (1,0) [0|0] "" Vector__XXX
 SG_ DLrpmRearLeft : 23|16@0- (1,0) [0|0] "" Vector__XXX
 SG_ DLrpmRearRight : 7|16@0- (1,0) [0|0] "" Vector__XXX

BO_ 256 DataloggerGPS: 8 Vector__XXX
 SG_ DLgpsLongitude : 39|32@0- (1,0) [0|0] "" Vector__XXX
 SG_ DLgpsLatitude : 7|32@0- (1,0) [0|0] "" Vector__XXX

BO_ 1317 EnergyMeterHeat: 6 Vector__XXX
 SG_ EMHeat : 23|32@0- (1,0) [0|0] "" Vector__XXX

BO_ 1318 EnergyMeterPower: 6 Vector__XXX
 SG_ EMPower : 23|32@0- (1,0) [0|0] "" Vector__XXX

BO_ 1313 EnergyMeterCurrent: 6 Vector__XXX
 SG_ EMCurrent : 23|32@0- (1,0) [0|0] "" Vector__XXX

BO_ 1314 EnergyMeterVoltageBattery: 6 Vector__XXX
 SG_ EMVoltage : 23|32@0- (1,0) [0|0] "" Vector__XXX

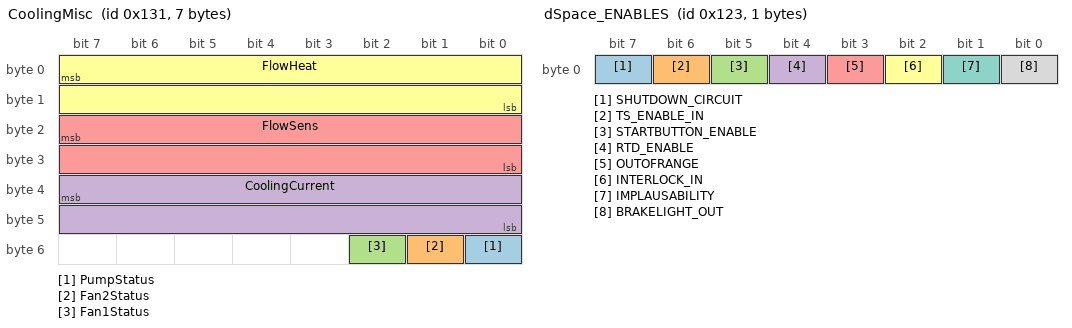
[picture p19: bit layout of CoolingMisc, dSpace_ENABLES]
BO_ 305 CoolingMisc: 7 Vector__XXX
 SG_ PumpStatus : 48|1@0- (1,0) [0|0] "" Vector__XXX
 SG_ Fan2Status : 49|1@0- (1,0) [0|0] "" Vector__XXX
 SG_ Fan1Status : 50|1@0- (1,0) [0|0] "" Vector__XXX
 SG_ CoolingCurrent : 39|16@0- (1,0) [0|0] "" Vector__XXX
 SG_ FlowSens : 23|16@0- (1,0) [0|0] "" Vector__XXX
 SG_ FlowHeat : 7|16@0- (1,0) [0|0] "" Vector__XXX

BO_ 304 CoolingHeatSens: 8 Vector__XXX
 SG_ HeatSens4 : 55|16@0- (1,0) [0|0] "" Vector__XXX
 SG_ HeatSens3 : 39|16@0- (1,0) [0|0] "" Vector__XXX
 SG_ HeatSens2 : 23|16@0- (1,0) [0|0] "" Vector__XXX
 SG_ HeatSense1 : 7|16@0- (1,0) [0|0] "" Vector__XXX

BO_ 291 dSpace_ENABLES: 1 Vector__XXX
 SG_ SHUTDOWN_CIRCUIT : 7|1@1- (1,0) [0|0] "" Vector__XXX
 SG_ TS_ENABLE_IN : 6|1@1- (1,0) [0|0] "" Vector__XXX
 SG_ STARTBUTTON_ENABLE : 5|1@1- (1,0) [0|0] "" Vector__XXX
 SG_ RTD_ENABLE : 4|1@1- (1,0) [0|0] "" Vector__XXX
 SG_ OUTOFRANGE : 3|1@1- (1,0) [0|0] "" Vector__XXX
 SG_ INTERLOCK_IN : 2|1@1- (1,0) [0|0] "" Vector__XXX
 SG_ IMPLAUSABILITY : 1|1@1- (1,0) [0|0] "" Vector__XXX
 SG_ BRAKELIGHT_OUT : 0|1@1- (1,0) [0|0] "" Vector__XXX

BO_ 290 dSpace_PEDALBOX_OUT: 4 Vector__XXX
 SG_ BRAKE_OUT : 16|16@1- (1,0) [0|0] "" Vector__XXX
 SG_ THROTTLE_OUT : 0|16@1- (1,0) [0|0] "" Vector__XXX

BO_ 289 dSpace_PEDALBOX_GAIN: 6 Vector__XXX
 SG_ BRAKE_GAIN : 32|16@1- (1,0) [0|0] "" Vector__XXX
 SG_ THROTTLE_2_GAIN : 16|16@1- (1,0) [0|0] "" Vector__XXX
 SG_ THROTTLE_1_GAIN : 0|16@1- (1,0) [0|0] "" Vector__XXX

BO_ 640 MC_ID_IQ: 4 Vector__XXX
 SG_ IQ_ACTUAL : 16|16@1- (1,0) [0|0] "" Vector__XXX
 SG_ ID_ACTUAL : 0|16@1- (1,0) [0|0] "" Vector__XXX

BO_ 624 MC_M_SET: 2 Vector__XXX
 SG_ M_SET : 0|12@1- (1,0) [0|0] "" Vector__XXX

BO_ 608 MC_VDC_BUS: 4 Vector__XXX
 SG_ VDC_BUS : 16|16@1- (1,0) [0|0] "" Vector__XXX

BO_ 592 MC_AIN_VALS: 4 Vector__XXX
 SG_ AIN_SCALED : 16|16@1- (1,0) [0|0] "" Vector__XXX

BO_ 560 MC_RESOLVER_ERROR: 2 Vector__XXX
 SG_ RESOLVER_ERROR : 0|16@1- (1,0) [0|0] "" Vector__XXX

BO_ 544 MC_Binary_Values: 6 Vector__XXX
 SG_ STATUS_BOOL : 16|32@1- (1,0) [0|0] "" Vector__XXX
 SG_ IN_OUT_BOOL : 0|16@1- (1,0) [0|0] "" Vector__XXX

BO_ 528 MC_I_VALUES: 8 Vector__XXX
 SG_ I_cmd_ramp : 48|16@1- (1,0) [0|0] "" Vector__XXX
 SG_ I_cmd : 32|16@1- (1,0) [0|0] "" Vector__XXX
 SG_ I_ACTUAL : 16|16@1- (1,0) [0|0] "" Vector__XXX
 SG_ I_ACT_FILT : 0|16@1- (1,0) [0|0] "" Vector__XXX

BO_ 288 dSpace_PEDALBOX_INPUTS: 6 Vector__XXX
 SG_ BREAK_VALUE : 32|16@1- (1,0) [0|0] "" Vector__XXX
 SG_ THROTTLE_2_IN : 16|16@1- (1,0) [0|0] "" Vector__XXX
 SG_ THROTTLE_1_IN : 0|16@1- (1,0) [0|0] "" Vector__XXX

BO_ 768 MC_TEMPERATURE: 6 Vector__XXX
 SG_ TEMP_AIR : 32|16@1- (1,0) [0|0] "" Vector__XXX
 SG_ TEMP_IGBT : 16|16@1- (1,0) [0|0] "" Vector__XXX
 SG_ TEMP_MOTOR : 0|16@1- (1,0) [0|0] "" Vector__XXX

BO_ 512 MC_N_VALUES: 8 Vector__XXX
 SG_ N_act_filt : 48|16@1- (1,0) [0|0] "" Vector__XXX
 SG_ N_cmd_ramp : 32|16@1- (1,0) [0|0] "" Vector__XXX
 SG_ N_cmd : 16|16@1- (1,0) [0|0] "" Vector__XXX
 SG_ N_ACTUAL : 0|16@1- (1,0) [0|5000] "" Vector__XXX

CM_ SG_ 7 New_Signal_405 "spark/";
CM_ SG_ 6 New_Signal_404 "spark/";
CM_ SG_ 5 New_Signal_403 "spark/";
CM_ SG_ 4 New_Signal_402 "spark/";
CM_ SG_ 3 New_Signal_401 "spark/";
CM_ SG_ 2 New_Signal_400 "spark/";
CM_ SG_ 1 New_Signal_399 "spark/";
CM_ SG_ 0 New_Signal_398 "spark/";
CM_ SG_ 260 DisplacementRearRight "spark/datalogger/displacement/displacementrearright";
CM_ SG_ 260 DisplacementRearLeft "spark/datalogger/displacement/displacementrearleft";
CM_ SG_ 260 DisplacementFrontRight "spark/datalogger/displacement/displacementfrontright";
CM_ SG_ 260 DisplacementFrontLeft "spark/datalogger/displacement/displacementfrontleft";
CM_ SG_ 1319 EMCurrentCounter "spark/energymeter/currentcounter/emcurrentcounter";
CM_ SG_ 321 AMSHighestTemperature "spark/accumulator/amsvalues1/amshighesttemperature";
CM_ SG_ 321 AMSLowestTemperature "spark/accumulator/amsvalues1/amslowesttemperature";
CM_ SG_ 321 AMSHighestVoltage "spark/accumulator/amsvalues1/amshighestvoltage";
CM_ SG_ 321 AMSLowestVoltage "spark/accumulator/amsvalues1/amslowestvoltage";
CM_ SG_ 1320 EMEnergy "spark/energymeter/energy/emenergy";
CM_ SG_ 1316 EMVoltage3 "spark/energymeter/voltage3/emvoltage3";
CM_ SG_ 1315 EMVoltageMC "spark/energymeter/voltagemc/emvoltagemc";
CM_ SG_ 1138 Voltage2 "spark/accumulator/voltage/143";
CM_ SG_ 1138 Voltage1 "spark/accumulator/voltage/144";
CM_ SG_ 1138 Heat2 "spark/accumulator/temperature/143";
CM_ SG_ 1138 Heat1 "spark/accumulator/temperature/144";
CM_ SG_ 1095 Voltage2 "spark/accumulator/voltage/141";
CM_ SG_ 1095 Voltage1 "spark/accumulator/voltage/142";
CM_ SG_ 1095 Heat2 "spark/accumulator/temperature/141";
CM_ SG_ 1095 Heat1 "spark/accumulator/temperature/142";
CM_ SG_ 1094 Voltage2 "spark/accumulator/voltage/139";
CM_ SG_ 1094 Voltage1 "spark/accumulator/voltage/140";
CM_ SG_ 1094 Heat2 "spark/accumulator/temperature/139";
CM_ SG_ 1094 Heat1 "spark/accumulator/temperature/140";
CM_ SG_ 1093 Voltage2 "spark/accumulator/voltage/137";
CM_ SG_ 1093 Voltage1 "spark/accumulator/voltage/138";
CM_ SG_ 1093 Heat2 "spark/accumulator/temperature/137";
CM_ SG_ 1093 Heat1 "spark/accumulator/temperature/138";
CM_ SG_ 1092 Voltage2 "spark/accumulator/voltage/135";
CM_ SG_ 1092 Voltage1 "spark/accumulator/voltage/136";
CM_ SG_ 1092 Heat2 "spark/accumulator/temperature/135";
CM_ SG_ 1092 Heat1 "spark/accumulator/temperature/136";
CM_ SG_ 1091 Voltage2 "spark/accumulator/voltage/133";
CM_ SG_ 1091 Voltage1 "spark/accumulator/voltage/134";
CM_ SG_ 1091 Heat2 "spark/accumulator/temperature/133";
CM_ SG_ 1091 Heat1 "spark/accumulator/temperature/134";
CM_ SG_ 1090 Voltage2 "spark/accumulator/voltage/131";
CM_ SG_ 1090 Voltage1 "spark/accumulator/voltage/132";
CM_ SG_ 1090 Heat2 "spark/accumulator/temperature/131";
CM_ SG_ 1090 Heat1 "spark/accumulator/temperature/132";
CM_ SG_ 1089 Voltage2 "spark/accumulator/voltage/129";
CM_ SG_ 1089 Voltage1 "spark/accumulator/voltage/130";
CM_ SG_ 1089 Heat2 "spark/accumulator/temperature/129";
CM_ SG_ 1089 Heat1 "spark/accumulator/temperature/130";
CM_ SG_ 1088 Voltage2 "spark/accumulator/voltage/127";
CM_ SG_ 1088 Voltage1 "spark/accumulator/voltage/128";
CM_ SG_ 1088 Heat2 "spark/accumulator/temperature/127";
CM_ SG_ 1088 Heat1 "spark/accumulator/temperature/128";
CM_ SG_ 1087 Voltage2 "spark/accumulator/voltage/125";
CM_ SG_ 1087 Voltage1 "spark/accumulator/voltage/126";
CM_ SG_ 1087 Heat2 "spark/accumulator/temperature/125";
CM_ SG_ 1087 Heat1 "spark/accumulator/temperature/126";
CM_ SG_ 1086 Voltage2 "spark/accumulator/voltage/123";
CM_ SG_ 1086 Voltage1 "spark/accumulator/voltage/124";
CM_ SG_ 1086 Heat2 "spark/accumulator/temperature/123";
CM_ SG_ 1086 Heat1 "spark/accumulator/temperature/124";
CM_ SG_ 1085 Voltage2 "spark/accumulator/voltage/121";
CM_ SG_ 1085 Voltage1 "spark/accumulator/voltage/122";
CM_ SG_ 1085 Heat2 "spark/accumulator/temperature/121";
CM_ SG_ 1085 Heat1 "spark/accumulator/temperature/122";
CM_ SG_ 1084 Voltage2 "spark/accumulator/voltage/119";
CM_ SG_ 1084 Voltage1 "spark/accumulator/voltage/120";
CM_ SG_ 1084 Heat2 "spark/accumulator/temperature/119";
CM_ SG_ 1084 Heat1 "spark/accumulator/temperature/120";
CM_ SG_ 1083 Voltage2 "spark/accumulator/voltage/117";
CM_ SG_ 1083 Voltage1 "spark/accumulator/voltage/118";
CM_ SG_ 1083 Heat2 "spark/accumulator/temperature/117";
CM_ SG_ 1083 Heat1 "spark/accumulator/temperature/118";
CM_ SG_ 1082 Voltage2 "spark/accumulator/voltage/115";
CM_ SG_ 1082 Voltage1 "spark/accumulator/voltage/116";
CM_ SG_ 1082 Heat2 "spark/accumulator/temperature/115";
CM_ SG_ 1082 Heat1 "spark/accumulator/temperature/116";
CM_ SG_ 1081 Voltage2 "spark/accumulator/voltage/113";
CM_ SG_ 1081 Voltage1 "spark/accumulator/voltage/114";
CM_ SG_ 1081 Heat2 "spark/accumulator/temperature/113";
CM_ SG_ 1081 Heat1 "spark/accumulator/temperature/114";
CM_ SG_ 1080 Voltage2 "spark/accumulator/voltage/111";
CM_ SG_ 1080 Voltage1 "spark/accumulator/voltage/112";
CM_ SG_ 1080 Heat2 "spark/accumulator/temperature/111";
CM_ SG_ 1080 Heat1 "spark/accumulator/temperature/112";
CM_ SG_ 1079 Voltage2 "spark/accumulator/voltage/109";
CM_ SG_ 1079 Voltage1 "spark/accumulator/voltage/110";
CM_ SG_ 1079 Heat2 "spark/accumulator/temperature/109";
CM_ SG_ 1079 Heat1 "spark/accumulator/temperature/110";
CM_ SG_ 1078 Voltage2 "spark/accumulator/voltage/107";
CM_ SG_ 1078 Voltage1 "spark/accumulator/voltage/108";
CM_ SG_ 1078 Heat2 "spark/accumulator/temperature/107";
CM_ SG_ 1078 Heat1 "spark/accumulator/temperature/108";
CM_ SG_ 1077 Voltage2 "spark/accumulator/voltage/105";
CM_ SG_ 1077 Voltage1 "spark/accumulator/voltage/106";
CM_ SG_ 1077 Heat2 "spark/accumulator/temperature/105";
CM_ SG_ 1077 Heat1 "spark/accumulator/temperature/106";
CM_ SG_ 1076 Voltage2 "spark/accumulator/voltage/103";
CM_ SG_ 1076 Voltage1 "spark/accumulator/voltage/104";
CM_ SG_ 1076 Heat2 "spark/accumulator/temperature/103";
CM_ SG_ 1076 Heat1 "spark/accumulator/temperature/104";
CM_ SG_ 1075 Voltage2 "spark/accumulator/voltage/101";
CM_ SG_ 1075 Voltage1 "spark/accumulator/voltage/102";
CM_ SG_ 1075 Heat2 "spark/accumulator/temperature/101";
CM_ SG_ 1075 Heat1 "spark/accumulator/temperature/102";
CM_ SG_ 1074 Voltage2 "spark/accumulator/voltage/99";
CM_ SG_ 1074 Voltage1 "spark/accumulator/voltage/100";
CM_ SG_ 1074 Heat2 "spark/accumulator/temperature/99";
CM_ SG_ 1074 Heat1 "spark/accumulator/temperature/100";
CM_ SG_ 1073 Voltage2 "spark/accumulator/voltage/97";
CM_ SG_ 1073 Voltage1 "spark/accumulator/voltage/98";
CM_ SG_ 1073 Heat2 "spark/accumulator/temperature/97";
CM_ SG_ 1073 Heat1 "spark/accumulator/temperature/98";
CM_ SG_ 1072 Voltage2 "spark/accumulator/voltage/95";
CM_ SG_ 1072 Voltage1 "spark/accumulator/voltage/96";
CM_ SG_ 1072 Heat2 "spark/accumulator/temperature/95";
CM_ SG_ 1072 Heat1 "spark/accumulator/temperature/96";
CM_ SG_ 1071 Voltage2 "spark/accumulator/voltage/93";
CM_ SG_ 1071 Voltage1 "spark/accumulator/voltage/94";
CM_ SG_ 1071 Heat2 "spark/accumulator/temperature/93";
CM_ SG_ 1071 Heat1 "spark/accumulator/temperature/94";
CM_ SG_ 1070 Voltage2 "spark/accumulator/voltage/91";
CM_ SG_ 1070 Voltage1 "spark/accumulator/voltage/92";
CM_ SG_ 1070 Heat2 "spark/accumulator/temperature/91";
CM_ SG_ 1070 Heat1 "spark/accumulator/temperature/92";
CM_ SG_ 1069 Voltage2 "spark/accumulator/voltage/89";
CM_ SG_ 1069 Voltage1 "spark/accumulator/voltage/90";
CM_ SG_ 1069 Heat2 "spark/accumulator/temperature/89";
CM_ SG_ 1069 Heat1 "spark/accumulator/temperature/90";
CM_ SG_ 1068 Voltage2 "spark/accumulator/voltage/87";
CM_ SG_ 1068 Voltage1 "spark/accumulator/voltage/88";
CM_ SG_ 1068 Heat2 "spark/accumulator/temperature/87";
CM_ SG_ 1068 Heat1 "spark/accumulator/temperature/88";
CM_ SG_ 1067 Voltage2 "spark/accumulator/voltage/85";
CM_ SG_ 1067 Voltage1 "spark/accumulator/voltage/86";
CM_ SG_ 1067 Heat2 "spark/accumulator/temperature/85";
CM_ SG_ 1067 Heat1 "spark/accumulator/temperature/86";
CM_ SG_ 1066 Voltage2 "spark/accumulator/voltage/83";
CM_ SG_ 1066 Voltage1 "spark/accumulator/voltage/84";
CM_ SG_ 1066 Heat2 "spark/accumulator/temperature/83";
CM_ SG_ 1066 Heat1 "spark/accumulator/temperature/84";
CM_ SG_ 1065 Voltage2 "spark/accumulator/voltage/81";
CM_ SG_ 1065 Voltage1 "spark/accumulator/voltage/82";
CM_ SG_ 1065 Heat2 "spark/accumulator/temperature/81";
CM_ SG_ 1065 Heat1 "spark/accumulator/temperature/82";
CM_ SG_ 1064 Voltage2 "spark/accumulator/voltage/79";
CM_ SG_ 1064 Voltage1 "spark/accumulator/voltage/80";
CM_ SG_ 1064 Heat2 "spark/accumulator/temperature/79";
CM_ SG_ 1064 Heat1 "spark/accumulator/temperature/80";
CM_ SG_ 1063 Voltage2 "spark/accumulator/voltage/77";
CM_ SG_ 1063 Voltage1 "spark/accumulator/voltage/78";
CM_ SG_ 1063 Heat2 "spark/accumulator/temperature/77";
CM_ SG_ 1063 Heat1 "spark/accumulator/temperature/78";
CM_ SG_ 1062 Voltage2 "spark/accumulator/voltage/75";
CM_ SG_ 1062 Voltage1 "spark/accumulator/voltage/76";
CM_ SG_ 1062 Heat2 "spark/accumulator/temperature/75";
CM_ SG_ 1062 Heat1 "spark/accumulator/temperature/76";
CM_ SG_ 1061 Voltage2 "spark/accumulator/voltage/73";
CM_ SG_ 1061 Voltage1 "spark/accumulator/voltage/74";
CM_ SG_ 1061 Heat2 "spark/accumulator/temperature/73";
CM_ SG_ 1061 Heat1 "spark/accumulator/temperature/74";
CM_ SG_ 1060 Voltage2 "spark/accumulator/voltage/71";
CM_ SG_ 1060 Voltage1 "spark/accumulator/voltage/72";
CM_ SG_ 1060 Heat2 "spark/accumulator/temperature/71";
CM_ SG_ 1060 Heat1 "spark/accumulator/temperature/72";
CM_ SG_ 1059 Voltage2 "spark/accumulator/voltage/69";
CM_ SG_ 1059 Voltage1 "spark/accumulator/voltage/70";
CM_ SG_ 1059 Heat2 "spark/accumulator/temperature/69";
CM_ SG_ 1059 Heat1 "spark/accumulator/temperature/70";
CM_ SG_ 1058 Voltage2 "spark/accumulator/voltage/67";
CM_ SG_ 1058 Voltage1 "spark/accumulator/voltage/68";
CM_ SG_ 1058 Heat2 "spark/accumulator/temperature/67";
CM_ SG_ 1058 Heat1 "spark/accumulator/temperature/68";
CM_ SG_ 1057 Voltage2 "spark/accumulator/voltage/65";
CM_ SG_ 1057 Voltage1 "spark/accumulator/voltage/66";
CM_ SG_ 1057 Heat2 "spark/accumulator/temperature/65";
CM_ SG_ 1057 Heat1 "spark/accumulator/temperature/66";
CM_ SG_ 1056 Voltage2 "spark/accumulator/voltage/63";
CM_ SG_ 1056 Voltage1 "spark/accumulator/voltage/64";
CM_ SG_ 1056 Heat2 "spark/accumulator/temperature/63";
CM_ SG_ 1056 Heat1 "spark/accumulator/temperature/64";
CM_ SG_ 1055 Voltage2 "spark/accumulator/voltage/61";
CM_ SG_ 1055 Voltage1 "spark/accumulator/voltage/62";
CM_ SG_ 1055 Heat2 "spark/accumulator/temperature/61";
CM_ SG_ 1055 Heat1 "spark/accumulator/temperature/62";
CM_ SG_ 1054 Voltage2 "spark/accumulator/voltage/59";
CM_ SG_ 1054 Voltage1 "spark/accumulator/voltage/60";
CM_ SG_ 1054 Heat2 "spark/accumulator/temperature/59";
CM_ SG_ 1054 Heat1 "spark/accumulator/temperature/60";
CM_ SG_ 1053 Voltage2 "spark/accumulator/voltage/57";
CM_ SG_ 1053 Voltage1 "spark/accumulator/voltage/58";
CM_ SG_ 1053 Heat2 "spark/accumulator/temperature/57";
CM_ SG_ 1053 Heat1 "spark/accumulator/temperature/58";
CM_ SG_ 1052 Voltage2 "spark/accumulator/voltage/55";
CM_ SG_ 1052 Voltage1 "spark/accumulator/voltage/56";
CM_ SG_ 1052 Heat2 "spark/accumulator/temperature/55";
CM_ SG_ 1052 Heat1 "spark/accumulator/temperature/56";
CM_ SG_ 1051 Voltage2 "spark/accumulator/voltage/53";
CM_ SG_ 1051 Voltage1 "spark/accumulator/voltage/54";
CM_ SG_ 1051 Heat2 "spark/accumulator/temperature/53";
CM_ SG_ 1051 Heat1 "spark/accumulator/temperature/54";
CM_ SG_ 1050 Voltage2 "spark/accumulator/voltage/51";
CM_ SG_ 1050 Voltage1 "spark/accumulator/voltage/52";
CM_ SG_ 1050 Heat2 "spark/accumulator/temperature/51";
CM_ SG_ 1050 Heat1 "spark/accumulator/temperature/52";
CM_ SG_ 1049 Voltage2 "spark/accumulator/voltage/49";
CM_ SG_ 1049 Voltage1 "spark/accumulator/voltage/50";
CM_ SG_ 1049 Heat2 "spark/accumulator/temperature/49";
CM_ SG_ 1049 Heat1 "spark/accumulator/temperature/50";
CM_ SG_ 1048 Voltage2 "spark/accumulator/voltage/47";
CM_ SG_ 1048 Voltage1 "spark/accumulator/voltage/48";
CM_ SG_ 1048 Heat2 "spark/accumulator/temperature/47";
CM_ SG_ 1048 Heat1 "spark/accumulator/temperature/48";
CM_ SG_ 1047 Voltage2 "spark/accumulator/voltage/45";
CM_ SG_ 1047 Voltage1 "spark/accumulator/voltage/46";
CM_ SG_ 1047 Heat2 "spark/accumulator/temperature/45";
CM_ SG_ 1047 Heat1 "spark/accumulator/temperature/46";
CM_ SG_ 1046 Voltage2 "spark/accumulator/voltage/43";
CM_ SG_ 1046 Voltage1 "spark/accumulator/voltage/44";
CM_ SG_ 1046 Heat2 "spark/accumulator/temperature/43";
CM_ SG_ 1046 Heat1 "spark/accumulator/temperature/44";
CM_ SG_ 1045 Voltage2 "spark/accumulator/voltage/41";
CM_ SG_ 1045 Voltage1 "spark/accumulator/voltage/42";
CM_ SG_ 1045 Heat2 "spark/accumulator/temperature/41";
CM_ SG_ 1045 Heat1 "spark/accumulator/temperature/42";
CM_ SG_ 1044 Voltage2 "spark/accumulator/voltage/39";
CM_ SG_ 1044 Voltage1 "spark/accumulator/voltage/40";
CM_ SG_ 1044 Heat2 "spark/accumulator/temperature/39";
CM_ SG_ 1044 Heat1 "spark/accumulator/temperature/40";
CM_ SG_ 1043 Voltage2 "spark/accumulator/voltage/37";
CM_ SG_ 1043 Voltage1 "spark/accumulator/voltage/38";
CM_ SG_ 1043 Heat2 "spark/accumulator/temperature/37";
CM_ SG_ 1043 Heat1 "spark/accumulator/temperature/38";
CM_ SG_ 1042 Voltage2 "spark/accumulator/voltage/35";
CM_ SG_ 1042 Voltage1 "spark/accumulator/voltage/36";
CM_ SG_ 1042 Heat2 "spark/accumulator/temperature/35";
CM_ SG_ 1042 Heat1 "spark/accumulator/temperature/36";
CM_ SG_ 1024 Voltage2 "spark/accumulator/voltage/33";
CM_ SG_ 1024 Voltage1 "spark/accumulator/voltage/34";
CM_ SG_ 1024 Heat2 "spark/accumulator/temperature/33";
CM_ SG_ 1024 Heat1 "spark/accumulator/temperature/34";
CM_ SG_ 1040 Voltage2 "spark/accumulator/voltage/31";
CM_ SG_ 1040 Voltage1 "spark/accumulator/voltage/32";
CM_ SG_ 1040 Heat2 "spark/accumulator/temperature/31";
CM_ SG_ 1040 Heat1 "spark/accumulator/temperature/32";
CM_ SG_ 1039 Voltage2 "spark/accumulator/voltage/29";
CM_ SG_ 1039 Voltage1 "spark/accumulator/voltage/30";
CM_ SG_ 1039 Heat2 "spark/accumulator/temperature/29";
CM_ SG_ 1039 Heat1 "spark/accumulator/temperature/30";
CM_ SG_ 1038 Voltage2 "spark/accumulator/voltage/27";
CM_ SG_ 1038 Voltage1 "spark/accumulator/voltage/28";
CM_ SG_ 1038 Heat2 "spark/accumulator/temperature/27";
CM_ SG_ 1038 Heat1 "spark/accumulator/temperature/28";
CM_ SG_ 1037 Voltage2 "spark/accumulator/voltage/25";
CM_ SG_ 1037 Voltage1 "spark/accumulator/voltage/26";
CM_ SG_ 1037 Heat2 "spark/accumulator/temperature/25";
CM_ SG_ 1037 Heat1 "spark/accumulator/temperature/26";
CM_ SG_ 1036 Voltage2 "spark/accumulator/voltage/23";
CM_ SG_ 1036 Voltage1 "spark/accumulator/voltage/24";
CM_ SG_ 1036 Heat2 "spark/accumulator/temperature/23";
CM_ SG_ 1036 Heat1 "spark/accumulator/temperature/24";
CM_ SG_ 1035 Voltage2 "spark/accumulator/voltage/21";
CM_ SG_ 1035 Voltage1 "spark/accumulator/voltage/22";
CM_ SG_ 1035 Heat2 "spark/accumulator/temperature/21";
CM_ SG_ 1035 Heat1 "spark/accumulator/temperature/22";
CM_ SG_ 1034 Voltage2 "spark/accumulator/voltage/19";
CM_ SG_ 1034 Voltage1 "spark/accumulator/voltage/20";
CM_ SG_ 1034 Heat2 "spark/accumulator/temperature/19";
CM_ SG_ 1034 Heat1 "spark/accumulator/temperature/20";
CM_ SG_ 1033 Voltage2 "spark/accumulator/voltage/17";
CM_ SG_ 1033 Voltage1 "spark/accumulator/voltage/18";
CM_ SG_ 1033 Heat2 "spark/accumulator/temperature/17";
CM_ SG_ 1033 Heat1 "spark/accumulator/temperature/18";
CM_ SG_ 1032 Voltage2 "spark/accumulator/voltage/15";
CM_ SG_ 1032 Voltage1 "spark/accumulator/voltage/16";
CM_ SG_ 1032 Heat2 "spark/accumulator/temperature/15";
CM_ SG_ 1032 Heat1 "spark/accumulator/temperature/16";
CM_ SG_ 1031 Voltage2 "spark/accumulator/voltage/13";
CM_ SG_ 1031 Voltage1 "spark/accumulator/voltage/14";
CM_ SG_ 1031 Heat2 "spark/accumulator/temperature/13";
CM_ SG_ 1031 Heat1 "spark/accumulator/temperature/14";
CM_ SG_ 1030 Voltage2 "spark/accumulator/voltage/11";
CM_ SG_ 1030 Voltage1 "spark/accumulator/voltage/12";
CM_ SG_ 1030 Heat2 "spark/accumulator/temperature/11";
CM_ SG_ 1030 Heat1 "spark/accumulator/temperature/12";
CM_ SG_ 1029 Voltage2 "spark/accumulator/voltage/9";
CM_ SG_ 1029 Voltage1 "spark/accumulator/voltage/10";
CM_ SG_ 1029 Heat2 "spark/accumulator/temperature/9";
CM_ SG_ 1029 Heat1 "spark/accumulator/temperature/10";
CM_ SG_ 1028 Voltage2 "spark/accumulator/voltage/7";
CM_ SG_ 1028 Voltage1 "spark/accumulator/voltage/8";
CM_ SG_ 1028 Heat2 "spark/accumulator/temperature/7";
CM_ SG_ 1028 Heat1 "spark/accumulator/temperature/8";
CM_ SG_ 1027 Voltage2 "spark/accumulator/voltage/5";
CM_ SG_ 1027 Voltage1 "spark/accumulator/voltage/6";
CM_ SG_ 1027 Heat2 "spark/accumulator/temperature/5";
CM_ SG_ 1027 Heat1 "spark/accumulator/temperature/6";
CM_ SG_ 1026 Voltage2 "spark/accumulator/voltage/3";
CM_ SG_ 1026 Voltage1 "spark/accumulator/voltage/4";
CM_ SG_ 1026 Heat2 "spark/accumulator/temperature/3";
CM_ SG_ 1026 Heat1 "spark/accumulator/temperature/4";
CM_ SG_ 1025 Voltage2 "spark/accumulator/voltage/1";
CM_ SG_ 1025 Voltage1 "spark/accumulator/voltage/2";
CM_ SG_ 1025 Heat2 "spark/accumulator/temperature/1";
CM_ SG_ 1025 Heat1 "spark/accumulator/temperature/2";
CM_ SG_ 322 BMSBadCellID "spark/accumulator/amsvalues2/bmsbadcellid";
CM_ SG_ 322 BMSTempPECCount "spark/accumulator/amsvalues2/bmstemppeccount";
CM_ SG_ 322 BMSVoltagePECCount "spark/accumulator/amsvalues2/bmsvoltagepeccount";
CM_ SG_ 322 BMSHighCurrentHerror "spark/accumulator/amsvalues2/bmshighcurrentherror";
CM_ SG_ 322 BMSLowCurrentError "spark/accumulator/amsvalues2/bmslowcurrenterror";
CM_ SG_ 322 BMSPECTempError "spark/accumulator/amsvalues2/bmspectemperror";
CM_ SG_ 322 BMSLowTempError "spark/accumulator/amsvalues2/bmslowtemperror";
CM_ SG_ 322 BMSHighTempError "spark/accumulator/amsvalues2/bmshightemperror";
CM_ SG_ 322 BMSPECVoltageError "spark/accumulator/amsvalues2/bmspecvoltageerror";
CM_ SG_ 322 BMSHighVoltageError "spark/accumulator/amsvalues2/bmshighvoltageerror";
CM_ SG_ 322 BMSLowVoltageError "spark/accumulator/amsvalues2/bmslowvoltageerror";
CM_ SG_ 322 AMSMeanVoltage "spark/accumulator/amsvalues2/amsmeanvoltage";
CM_ SG_ 322 AMStsmsOut "spark/accumulator/amsvalues2/amstsmsout";
CM_ SG_ 322 AMSstatus4 "spark/accumulator/amsvalues2/amsstatus4";
CM_ SG_ 322 AMSstatus3 "spark/accumulator/amsvalues2/amsstatus3";
CM_ SG_ 322 AMSstatus2 "spark/accumulator/amsvalues2/amsstatus2";
CM_ SG_ 322 AMSstatus1 "spark/accumulator/amsvalues2/amsstatus1";
CM_ SG_ 322 AMSsdcTrigger "spark/accumulator/amsvalues2/amssdctrigger";
CM_ SG_ 322 AMSsdcReset "spark/accumulator/amsvalues2/amssdcreset";
CM_ SG_ 322 AMSindicatorReset "spark/accumulator/amsvalues2/amsindicatorreset";
CM_ SG_ 322 AMSindicator "spark/accumulator/amsvalues2/amsindicator";
CM_ SG_ 322 AMSimdIndicator "spark/accumulator/amsvalues2/amsimdindicator";
CM_ SG_ 322 AMSimdError "spark/accumulator/amsvalues2/amsimderror";
CM_ SG_ 322 AMSerror "spark/accumulator/amsvalues2/amserror";
CM_ SG_ 322 AMSdriverReset "spark/accumulator/amsvalues2/amsdriverreset";
CM_ SG_ 322 AMSairGround "spark/accumulator/amsvalues2/amsairground";
CM_ SG_ 322 AMSaccFanControl "spark/accumulator/amsvalues2/amsaccfancontrol";
CM_ SG_ 320 AMSboardTemp "spark/accumulator/amstempcurrent/amsboardtemp";
CM_ SG_ 320 AMSCurrent "spark/accumulator/amstempcurrent/amscurrent";
CM_ SG_ 320 AMSDCDCtemp "spark/accumulator/amstempcurrent/amsdcdctemp";
CM_ SG_ 320 AMSHumidity "spark/accumulator/amstempcurrent/amshumidity";
CM_ SG_ 273 TSALair2 "spark/junction/misc/tsalair2";
CM_ SG_ 273 TSALair1 "spark/junction/misc/tsalair1";
CM_ SG_ 273 TSALpreCharge "spark/junction/misc/tsalprecharge";
CM_ SG_ 273 TSALacc "spark/junction/misc/tsalacc";
CM_ SG_ 273 JSafeState "spark/junction/misc/jsafestate";
CM_ SG_ 273 JImplausability "spark/junction/misc/jimplausability";
CM_ SG_ 273 TSALmc "spark/junction/misc/tsalmc";
CM_ SG_ 273 JHumidity "spark/junction/misc/jhumidity";
CM_ SG_ 273 JDRS2 "spark/junction/misc/jdrs2";
CM_ SG_ 273 JDRS1 "spark/junction/misc/jdrs1";
CM_ SG_ 273 JCurrent24Vfused "spark/junction/misc/jcurrent24vfused";
CM_ SG_ 272 JCurrentMClv "spark/junction/current/jcurrentmclv";
CM_ SG_ 272 JCurrentdSpace "spark/junction/current/jcurrentdspace";
CM_ SG_ 272 JCurrent5V "spark/junction/current/jcurrent5v";
CM_ SG_ 272 JCurrent12V "spark/junction/current/jcurrent12v";
CM_ SG_ 336 DBButton2 "spark/dashboard/dasboardbuttons/dbbutton2";
CM_ SG_ 336 DBButton1 "spark/dashboard/dasboardbuttons/dbbutton1";
CM_ SG_ 258 DLgpsSpeed "spark/datalogger/acceleration/dlgpsspeed";
CM_ SG_ 258 DLSteeringAngle "spark/datalogger/acceleration/dlsteeringangle";
CM_ SG_ 258 DLLinlineAcceleration "spark/datalogger/acceleration/dllinlineacceleration";
CM_ SG_ 258 DLLateralAcceleration "spark/datalogger/acceleration/dllateralacceleration";
CM_ SG_ 259 DLLaptime "spark/datalogger/laptime/dllaptime";
CM_ SG_ 257 DLrpmFrontLeft "spark/datalogger/rpm/dlrpmfrontleft";
CM_ SG_ 257 DLrpmFrontRight "spark/datalogger/rpm/dlrpmfrontright";
CM_ SG_ 257 DLrpmRearLeft "spark/datalogger/rpm/dlrpmrearleft";
CM_ SG_ 257 DLrpmRearRight "spark/datalogger/rpm/dlrpmrearright";
CM_ SG_ 256 DLgpsLongitude "spark/datalogger/gps/dlgpslongitude";
CM_ SG_ 256 DLgpsLatitude "spark/datalogger/gps/dlgpslatitude";
CM_ SG_ 1317 EMHeat "spark/energymeter/heat/emheat";
CM_ SG_ 1318 EMPower "spark/energymeter/power/empower";
CM_ SG_ 1313 EMCurrent "spark/energymeter/current/emcurrent";
CM_ SG_ 1314 EMVoltage "spark/energymeter/voltagebattery/emvoltage";
CM_ SG_ 305 PumpStatus "spark/cooling/misc/pumpstatus";
CM_ SG_ 305 Fan2Status "spark/cooling/misc/fan2status";
CM_ SG_ 305 Fan1Status "spark/cooling/misc/fan1status";
CM_ SG_ 305 CoolingCurrent "spark/cooling/misc/coolingcurrent";
CM_ SG_ 305 FlowSens "spark/cooling/misc/flowsens";
CM_ SG_ 305 FlowHeat "spark/cooling/misc/flowheat";
CM_ SG_ 304 HeatSens4 "spark/cooling/heatsens/heatsens4";
CM_ SG_ 304 HeatSens3 "spark/cooling/heatsens/heatsens3";
CM_ SG_ 304 HeatSens2 "spark/cooling/heatsens/heatsens2";
CM_ SG_ 304 HeatSense1 "spark/cooling/heatsens/heatsense1";
CM_ SG_ 291 SHUTDOWN_CIRCUIT "spark/dspace/_enables/shutdown_circuit";
CM_ SG_ 291 TS_ENABLE_IN "spark/dspace/_enables/ts_enable_in";
CM_ SG_ 291 STARTBUTTON_ENABLE "spark/dspace/_enables/startbutton_enable";
CM_ SG_ 291 RTD_ENABLE "spark/dspace/_enables/rtd_enable";
CM_ SG_ 291 OUTOFRANGE "spark/dspace/_enables/outofrange";
CM_ SG_ 291 INTERLOCK_IN "spark/dspace/_enables/interlock_in";
CM_ SG_ 291 IMPLAUSABILITY "spark/dspace/_enables/implausability";
CM_ SG_ 291 BRAKELIGHT_OUT "spark/dspace/_enables/brakelight_out";
CM_ SG_ 290 BRAKE_OUT "spark/dspace/_pedalbox_out/brake_out";
CM_ SG_ 290 THROTTLE_OUT "spark/dspace/_pedalbox_out/throttle_out";
CM_ SG_ 289 BRAKE_GAIN "spark/dspace/_pedalbox_gain/brake_gain";
CM_ SG_ 289 THROTTLE_2_GAIN "spark/dspace/_pedalbox_gain/throttle_2_gain";
CM_ SG_ 289 THROTTLE_1_GAIN "spark/dspace/_pedalbox_gain/throttle_1_gain";
CM_ SG_ 640 IQ_ACTUAL "spark/mc/_id_iq/iq_actual";
CM_ SG_ 640 ID_ACTUAL "spark/mc/_id_iq/id_actual";
CM_ SG_ 624 M_SET "spark/mc/_m_set/m_set";
CM_ SG_ 608 VDC_BUS "spark/mc/_vdc_bus/vdc_bus";
CM_ BO_ 592 "Test/dspace";
CM_ SG_ 592 AIN_SCALED "spark/mc/_ain_vals/ain_scaled";
CM_ SG_ 560 RESOLVER_ERROR "spark/mc/_resolver_error/resolver_error";
CM_ SG_ 544 STATUS_BOOL "spark/mc/_binary_values/status_bool";
CM_ SG_ 544 IN_OUT_BOOL "spark/mc/_binary_values/in_out_bool";
CM_ SG_ 528 I_cmd_ramp "spark/mc/_i_values/i_cmd_ramp";
CM_ SG_ 528 I_cmd "spark/mc/_i_values/i_cmd";
CM_ SG_ 528 I_ACTUAL "spark/mc/_i_values/i_actual";
CM_ SG_ 528 I_ACT_FILT "spark/mc/_i_values/i_act_filt";
CM_ SG_ 288 BREAK_VALUE "spark/dspace/_pedalbox_inputs/break_value";
CM_ SG_ 288 THROTTLE_2_IN "spark/dspace/_pedalbox_inputs/throttle_2_in";
CM_ SG_ 288 THROTTLE_1_IN "spark/dspace/_pedalbox_inputs/throttle_1_in";
CM_ SG_ 768 TEMP_AIR "spark/mc/_temperature/temp_air";
CM_ SG_ 768 TEMP_IGBT "spark/mc/_temperature/temp_igbt";
CM_ SG_ 768 TEMP_MOTOR "spark/mc/_temperature/temp_motor";
CM_ SG_ 512 N_act_filt "spark/mc/_n_values/n_act_filt";
CM_ SG_ 512 N_cmd_ramp "spark/mc/_n_values/n_cmd_ramp";
CM_ SG_ 512 N_cmd "spark/mc/_n_values/n_cmd";
CM_ SG_ 512 N_ACTUAL "spark/mc/_n_values/n_actual";
BA_DEF_  "BusType" STRING ;
BA_DEF_DEF_  "BusType" "CAN";
